VERSION "..\..\trunk\components\winTestMT\code\canApi\dbcFiles\canBus_04.dbc, created by Octave and generateRandomDbc.m on 21-Feb-2017"

NS_ :

BS_:

BU_: ECU

BO_ 577 frame_577: 2 Vector__XXX
  SG_ checksum_9_8 : 8|8@1+ (1.0,0.0) [0.0|255.0] "" ECU

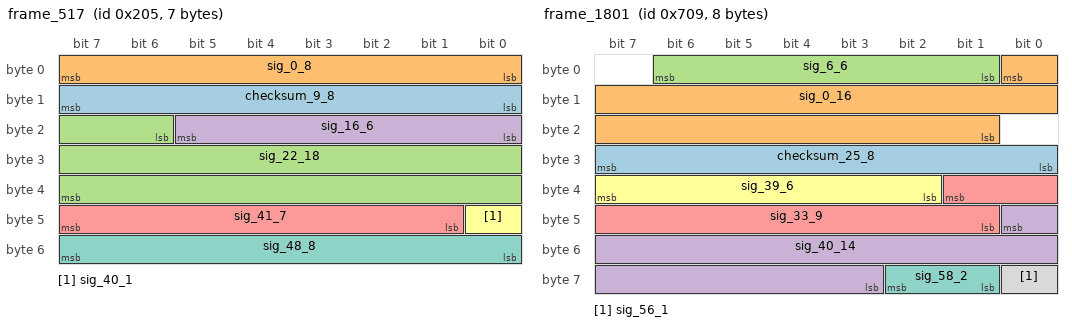
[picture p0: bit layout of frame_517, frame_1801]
BO_ 517 frame_517: 7 Vector__XXX
  SG_ checksum_9_8 : 8|8@1+ (1.0,0.0) [0.0|255.0] "" ECU
  SG_ sig_0_8 : 0|8@1- (1.0,0.0) [-128.0|126.0] "" ECU
  SG_ sig_22_18 : 22|18@1- (1.0,0.0) [-131072.0|131070.0] "" ECU
  SG_ sig_16_6 : 16|6@1- (1.0,0.0) [-32.0|30.0] "" ECU
  SG_ sig_41_7 : 41|7@1+ (0.010000000000000002,0.0) [0.0|1.2600000000000002] "V" ECU
  SG_ sig_40_1 : 40|1@1+ (1.0,0.0) [0.0|1.0] "" ECU
  SG_ sig_48_8 : 48|8@1- (0.1,0.0) [-12.8|12.600000000000001] "kWh" ECU

BO_ 1470 frame_1470: 4 Vector__XXX
  SG_ checksum_25_8 : 31|8@0+ (1.0,0.0) [0.0|255.0] "" ECU
  SG_ sig_4_12 : 4|12@0+ (1.0,0.0) [0.0|4094.0] "" ECU
  SG_ sig_5_3 : 5|3@1- (1.0,0.0) [-4.0|2.0] "" ECU
  SG_ sig_8_1 : 8|1@1+ (1.0,0.0) [0.0|1.0] "" ECU
  SG_ sig_23_6 : 23|6@0+ (1000.0,0.0) [0.0|62000.0] "kWh" ECU
  SG_ sig_16_2 : 16|2@1+ (1.0,0.0) [0.0|3.0] "" ECU

BO_ 1189 frame_1189: 8 Vector__XXX
  SG_ checksum_49_8 : 55|8@0+ (1.0,0.0) [0.0|255.0] "" ECU
  SG_ sig_29_22 : 29|22@0+ (1.0000000000000014E-12,-3.162277660168379E-6) [-3.162277660168379E-6|1.032024339831627E-6] "V" ECU
  SG_ sig_3_20 : 3|20@0- (1.0,0.0) [-524288.0|524286.0] "" ECU
  SG_ sig_7_3 : 7|3@0+ (1.0,0.0) [0.0|6.0] "" ECU
  SG_ sig_31_2 : 31|2@0+ (1.0,0.0) [0.0|3.0] "" ECU
  SG_ sig_63_8 : 63|8@0- (1.0000000000000006E-6,-3.1622776601683795E-5) [-1.5962277660168386E-4|9.437722339831629E-5] "m/s^2" ECU

BO_ 1801 frame_1801: 8 ECU
  SG_ checksum_25_8 : 31|8@0+ (1.0,0.0) [0.0|255.0] "" Vector__XXX
  SG_ sig_0_16 : 0|16@0- (1.0,0.0) [-32768.0|32766.0] "" Vector__XXX
  SG_ sig_6_6 : 6|6@0- (1.0,31.622776601683793) [-0.37722339831620744|61.622776601683796] "W" Vector__XXX
  SG_ sig_40_14 : 40|14@0+ (0.0010000000000000002,3.1622776601683795) [3.1622776601683795|19.544277660168383] "s" Vector__XXX
  SG_ sig_33_9 : 33|9@0+ (1.0000000000000007E-7,0.0) [0.0|5.100000000000004E-5] "km/h" Vector__XXX
  SG_ sig_39_6 : 39|6@0- (1.0000000000000007E-7,3.162277660168379E-6) [-3.7722339831623205E-8|6.162277660168381E-6] "kWh" Vector__XXX
  SG_ sig_58_2 : 58|2@0- (1.0,0.0) [-2.0|1.0] "" Vector__XXX
  SG_ sig_56_1 : 56|1@0+ (1.0,0.0) [0.0|1.0] "" Vector__XXX

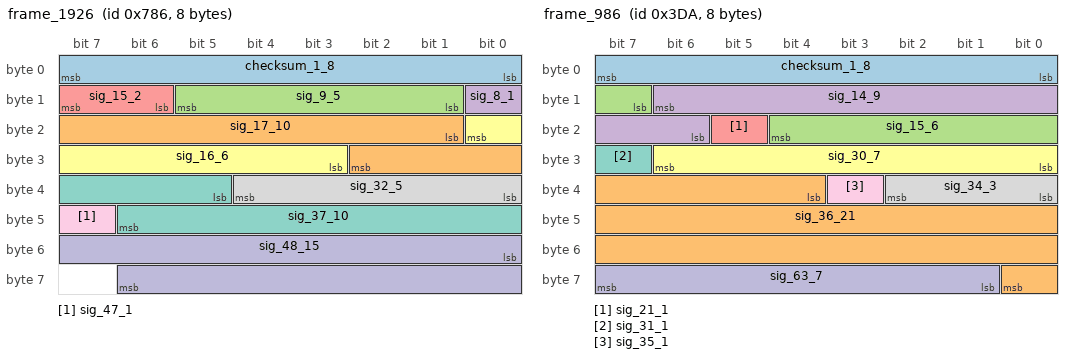
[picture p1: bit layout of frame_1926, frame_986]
BO_ 1926 frame_1926: 8 ECU
  SG_ checksum_1_8 : 7|8@0+ (1.0,0.0) [0.0|255.0] "" Vector__XXX
  SG_ sig_17_10 : 17|10@1- (1.0000000000000005E-4,0.0) [-0.05120000000000002|0.051000000000000024] "W" Vector__XXX
  SG_ sig_9_5 : 9|5@1+ (1.0,0.0) [0.0|30.0] "" Vector__XXX
  SG_ sig_8_1 : 8|1@1+ (1.0,0.0) [0.0|1.0] "" Vector__XXX
  SG_ sig_15_2 : 15|2@0- (1.0,0.0) [-2.0|1.0] "" Vector__XXX
  SG_ sig_16_6 : 16|6@0- (1.0000000000000006E-5,0.0) [-3.200000000000002E-4|3.000000000000002E-4] "m/s^2" Vector__XXX
  SG_ sig_37_10 : 37|10@1- (1.0000000000000007E-7,3.1622776601683795E-5) [-1.9577223398316243E-5|8.262277660168384E-5] "s" Vector__XXX
  SG_ sig_32_5 : 32|5@1- (1.0000000000000006E-6,0.0) [-1.600000000000001E-5|1.4000000000000008E-5] "m/s^2" Vector__XXX
  SG_ sig_47_1 : 47|1@0+ (1.0,0.0) [0.0|1.0] "" Vector__XXX
  SG_ sig_48_15 : 48|15@1- (0.0010000000000000002,31.622776601683793) [15.238776601683789|48.0047766016838] "W" Vector__XXX

BO_ 986 frame_986: 8 ECU
  SG_ checksum_1_8 : 7|8@0+ (1.0,0.0) [0.0|255.0] "" Vector__XXX
  SG_ sig_36_21 : 36|21@1- (0.010000000000000002,3162.2776601683795) [-7323.482339831622|13648.017660168382] "A" Vector__XXX
  SG_ sig_15_6 : 15|6@1- (1.0,0.0) [-32.0|30.0] "" Vector__XXX
  SG_ sig_14_9 : 14|9@0- (1.0,0.0) [-256.0|254.0] "" Vector__XXX
  SG_ sig_21_1 : 21|1@1+ (1.0,0.0) [0.0|1.0] "" Vector__XXX
  SG_ sig_30_7 : 30|7@0- (1.0000000000000006E-6,3.1622776601683795E-5) [-3.237722339831624E-5|9.362277660168383E-5] "V" Vector__XXX
  SG_ sig_31_1 : 31|1@0+ (1.0,0.0) [0.0|1.0] "" Vector__XXX
  SG_ sig_34_3 : 34|3@0- (1.0,0.0) [-4.0|2.0] "" Vector__XXX
  SG_ sig_35_1 : 35|1@0+ (1.0,0.0) [0.0|1.0] "" Vector__XXX
  SG_ sig_63_7 : 63|7@0+ (0.0010000000000000002,0.0) [0.0|0.12600000000000003] "km/h" Vector__XXX

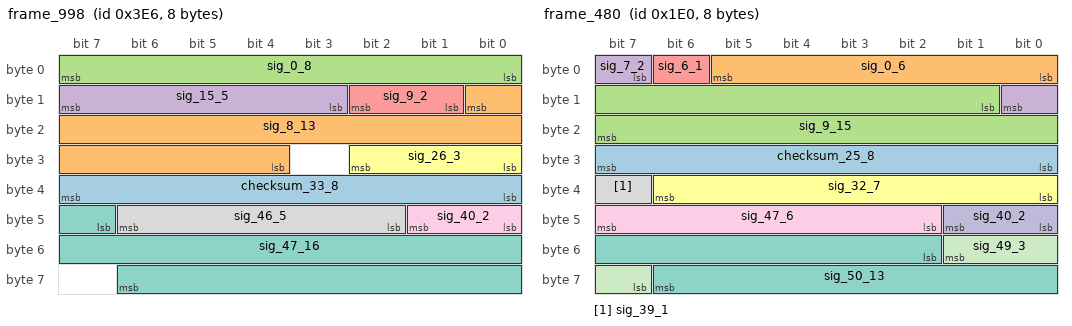
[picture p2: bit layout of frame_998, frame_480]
BO_ 998 frame_998: 8 ECU
  SG_ checksum_33_8 : 39|8@0+ (1.0,0.0) [0.0|255.0] "" Vector__XXX
  SG_ sig_8_13 : 8|13@0- (10.0,-31622.776601683792) [-72582.77660168378|9317.223398316208] "km/h" Vector__XXX
  SG_ sig_0_8 : 0|8@1+ (1.0,0.0) [0.0|254.0] "" Vector__XXX
  SG_ sig_15_5 : 15|5@0+ (1.0000000000000006E-5,3.1622776601683794E-4) [3.1622776601683794E-4|6.162277660168381E-4] "W" Vector__XXX
  SG_ sig_9_2 : 9|2@1+ (1.0,0.0) [0.0|3.0] "" Vector__XXX
  SG_ sig_26_3 : 26|3@0+ (1.0,0.0) [0.0|6.0] "" Vector__XXX
  SG_ sig_47_16 : 47|16@1- (0.010000000000000002,0.0) [-327.68000000000006|327.6600000000001] "s" Vector__XXX
  SG_ sig_46_5 : 46|5@0- (1.0000000000000005E-4,-0.0031622776601683794) [-0.0047622776601683806|-0.0017622776601683788] "m/s^2" Vector__XXX
  SG_ sig_40_2 : 40|2@1- (1.0,0.0) [-2.0|1.0] "" Vector__XXX

BO_ 480 frame_480: 8 Vector__XXX
  SG_ checksum_25_8 : 31|8@0+ (1.0,0.0) [0.0|255.0] "" ECU
  SG_ sig_0_6 : 0|6@1+ (1.0,0.0) [0.0|62.0] "" ECU
  SG_ sig_9_15 : 9|15@1+ (1.0000000000000005E-4,0.0) [0.0|3.2766000000000015] "kWh" ECU
  SG_ sig_7_2 : 7|2@1- (1.0,0.0) [-2.0|1.0] "" ECU
  SG_ sig_6_1 : 6|1@0+ (1.0,0.0) [0.0|1.0] "" ECU
  SG_ sig_32_7 : 32|7@1+ (0.1,3.1622776601683795) [3.1622776601683795|15.762277660168381] "m/s^2" ECU
  SG_ sig_50_13 : 50|13@1- (1.0,0.0) [-4096.0|4094.0] "" ECU
  SG_ sig_39_1 : 39|1@0+ (1.0,0.0) [0.0|1.0] "" ECU
  SG_ sig_47_6 : 47|6@0+ (1.0,0.0) [0.0|62.0] "km/h" ECU
  SG_ sig_40_2 : 40|2@1- (1.0,0.0) [-2.0|1.0] "" ECU
  SG_ sig_49_3 : 49|3@0- (1.0,0.0) [-4.0|2.0] "" ECU

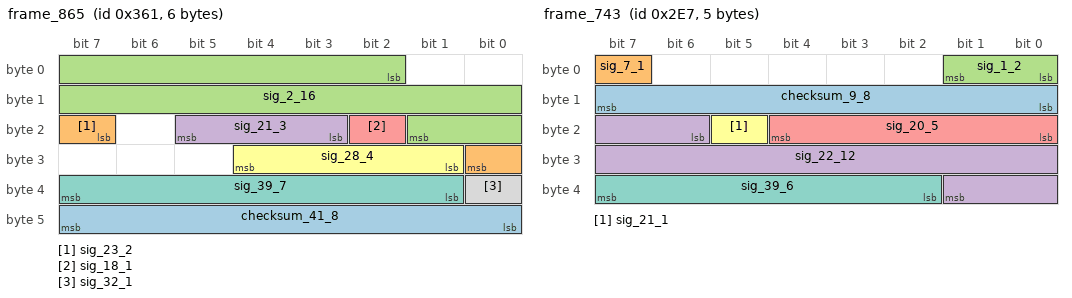
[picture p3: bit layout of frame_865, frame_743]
BO_ 865 frame_865: 6 Vector__XXX
  SG_ checksum_41_8 : 40|8@1+ (1.0,0.0) [0.0|255.0] "" ECU
  SG_ sig_23_2 : 23|2@1- (1.0,0.0) [-2.0|1.0] "" ECU
  SG_ sig_2_16 : 2|16@1- (1.0000000000000006E-6,0.03162277660168379) [-0.001145223398316228|0.06438877660168381] "km/h" ECU
  SG_ sig_21_3 : 21|3@0+ (1.0,0.0) [0.0|6.0] "" ECU
  SG_ sig_18_1 : 18|1@1+ (1.0,0.0) [0.0|1.0] "" ECU
  SG_ sig_28_4 : 28|4@0+ (1000.0,-3162.2776601683795) [-3162.2776601683795|10837.72233983162] "V" ECU
  SG_ sig_39_7 : 39|7@0+ (0.1,-3.1622776601683795) [-3.1622776601683795|9.437722339831621] "m/s^2" ECU
  SG_ sig_32_1 : 32|1@0+ (1.0,0.0) [0.0|1.0] "" ECU

BO_ 743 frame_743: 5 ECU
  SG_ checksum_9_8 : 8|8@1+ (1.0,0.0) [0.0|255.0] "" Vector__XXX
  SG_ sig_7_1 : 7|1@0+ (1.0,0.0) [0.0|1.0] "" Vector__XXX
  SG_ sig_1_2 : 1|2@0- (1.0,0.0) [-2.0|1.0] "" Vector__XXX
  SG_ sig_22_12 : 22|12@1+ (1.0,0.0) [0.0|4094.0] "" Vector__XXX
  SG_ sig_20_5 : 20|5@0+ (1.0,31.622776601683793) [31.622776601683793|61.622776601683796] "m/s^2" Vector__XXX
  SG_ sig_21_1 : 21|1@0+ (1.0,0.0) [0.0|1.0] "" Vector__XXX
  SG_ sig_39_6 : 39|6@0+ (1.0,0.0) [0.0|62.0] "" Vector__XXX

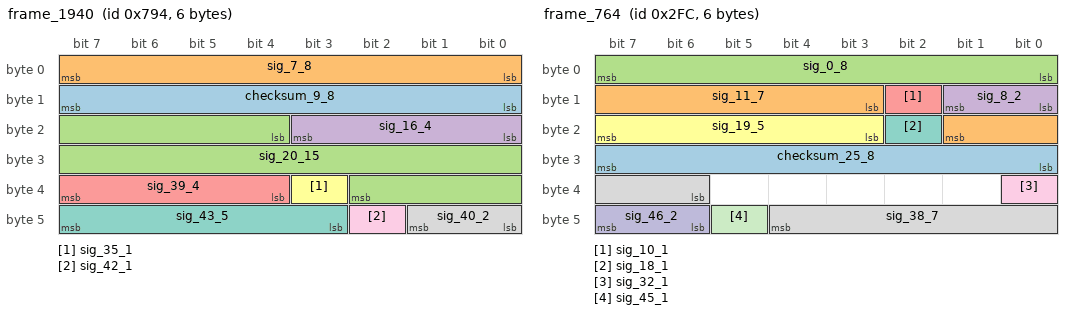
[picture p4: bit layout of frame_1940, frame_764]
BO_ 1940 frame_1940: 6 Vector__XXX
  SG_ checksum_9_8 : 8|8@1+ (1.0,0.0) [0.0|255.0] "" ECU
  SG_ sig_7_8 : 7|8@0- (100.0,3162.2776601683795) [-9637.72233983162|15762.27766016838] "km/h" ECU
  SG_ sig_20_15 : 20|15@1- (1.0000000000000006E-5,0.31622776601683794) [0.15238776601683784|0.4800477660168381] "m/s^2" ECU
  SG_ sig_16_4 : 16|4@1- (1.0000000000000006E-6,3.162277660168379E-6) [-4.8377223398316255E-6|9.162277660168383E-6] "m/s^2" ECU
  SG_ sig_39_4 : 39|4@0+ (1000.0,3162.2776601683795) [3162.2776601683795|17162.27766016838] "V" ECU
  SG_ sig_35_1 : 35|1@0+ (1.0,0.0) [0.0|1.0] "" ECU
  SG_ sig_43_5 : 43|5@1- (10.0,316.22776601683796) [156.22776601683796|456.22776601683796] "kWh" ECU
  SG_ sig_40_2 : 40|2@1+ (1.0,0.0) [0.0|3.0] "" ECU
  SG_ sig_42_1 : 42|1@0+ (1.0,0.0) [0.0|1.0] "" ECU

BO_ 764 frame_764: 6 Vector__XXX
  SG_ checksum_25_8 : 24|8@1+ (1.0,0.0) [0.0|255.0] "" ECU
  SG_ sig_11_7 : 11|7@1+ (1.0000000000000006E-5,-3.1622776601683794E-4) [-3.1622776601683794E-4|9.437722339831628E-4] "W" ECU
  SG_ sig_0_8 : 0|8@1- (1.0000000000000005E-4,-0.0031622776601683794) [-0.015962277660168386|0.009437722339831625] "kWh" ECU
  SG_ sig_8_2 : 8|2@1- (1.0,0.0) [-2.0|1.0] "" ECU
  SG_ sig_10_1 : 10|1@1+ (1.0,0.0) [0.0|1.0] "" ECU
  SG_ sig_19_5 : 19|5@1+ (1.0,0.0) [0.0|30.0] "" ECU
  SG_ sig_18_1 : 18|1@1+ (1.0,0.0) [0.0|1.0] "" ECU
  SG_ sig_38_7 : 38|7@1- (100.0,3162.2776601683795) [-3237.7223398316205|9362.27766016838] "W" ECU
  SG_ sig_32_1 : 32|1@1+ (1.0,0.0) [0.0|1.0] "" ECU
  SG_ sig_46_2 : 46|2@1- (1.0,0.0) [-2.0|1.0] "" ECU
  SG_ sig_45_1 : 45|1@1+ (1.0,0.0) [0.0|1.0] "" ECU

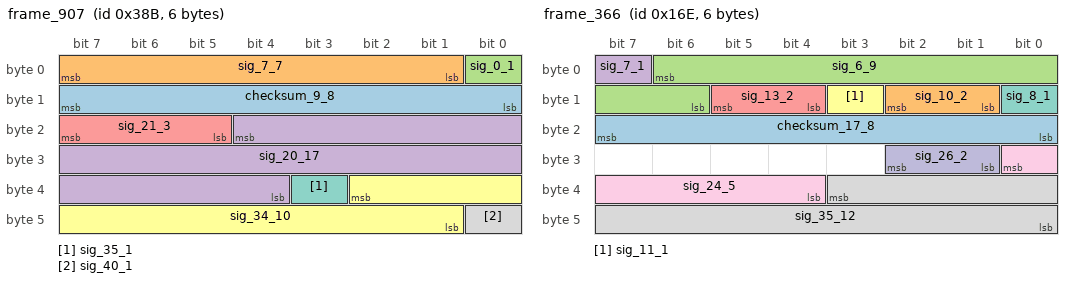
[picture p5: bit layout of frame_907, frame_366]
BO_ 907 frame_907: 6 Vector__XXX
  SG_ checksum_9_8 : 8|8@1+ (1.0,0.0) [0.0|255.0] "" ECU
  SG_ sig_7_7 : 7|7@0+ (1.0000000000000006E-6,3.1622776601683795E-5) [3.1622776601683795E-5|1.5762277660168387E-4] "km/h" ECU
  SG_ sig_0_1 : 0|1@0+ (1.0,0.0) [0.0|1.0] "" ECU
  SG_ sig_20_17 : 20|17@0- (0.1,3162.2776601683795) [-3391.322339831621|9715.67766016838] "m/s^2" ECU
  SG_ sig_21_3 : 21|3@1+ (1.0,0.0) [0.0|6.0] "" ECU
  SG_ sig_34_10 : 34|10@0- (1.0,0.0) [-512.0|510.0] "" ECU
  SG_ sig_35_1 : 35|1@1+ (1.0,0.0) [0.0|1.0] "" ECU
  SG_ sig_40_1 : 40|1@0+ (1.0,0.0) [0.0|1.0] "" ECU

BO_ 366 frame_366: 6 Vector__XXX
  SG_ checksum_17_8 : 23|8@0+ (1.0,0.0) [0.0|255.0] "" ECU
  SG_ sig_10_2 : 10|2@0- (1.0,0.0) [-2.0|1.0] "" ECU
  SG_ sig_6_9 : 6|9@0- (1.0,0.0) [-256.0|254.0] "" ECU
  SG_ sig_7_1 : 7|1@0+ (1.0,0.0) [0.0|1.0] "" ECU
  SG_ sig_13_2 : 13|2@0+ (1.0,0.0) [0.0|3.0] "" ECU
  SG_ sig_11_1 : 11|1@0+ (1.0,0.0) [0.0|1.0] "" ECU
  SG_ sig_8_1 : 8|1@0+ (1.0,0.0) [0.0|1.0] "" ECU
  SG_ sig_35_12 : 35|12@0+ (1.0000000000000005E-4,-0.31622776601683794) [-0.31622776601683794|0.09317223398316227] "V" ECU
  SG_ sig_24_5 : 24|5@0- (1.0000000000000007E-7,3.162277660168379E-6) [1.562277660168378E-6|4.56227766016838E-6] "W" ECU
  SG_ sig_26_2 : 26|2@0- (1.0,0.0) [-2.0|1.0] "" ECU

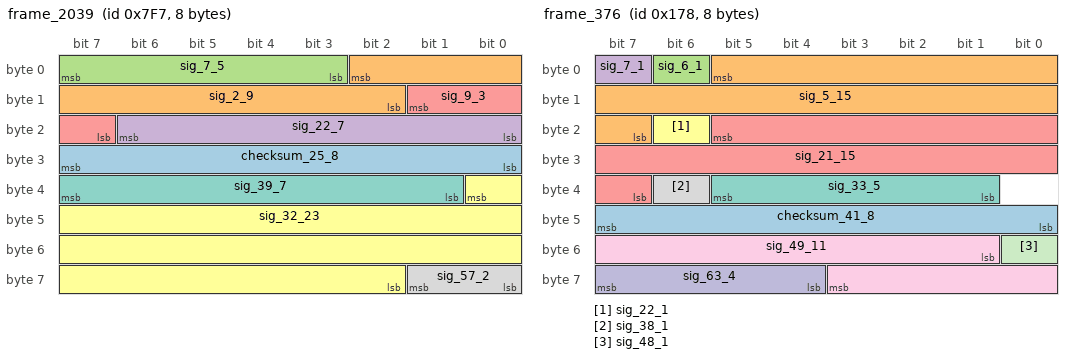
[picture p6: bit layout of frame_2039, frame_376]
BO_ 2039 frame_2039: 8 Vector__XXX
  SG_ checksum_25_8 : 24|8@1+ (1.0,0.0) [0.0|255.0] "" ECU
  SG_ sig_2_9 : 2|9@0- (1.0,0.0) [-256.0|254.0] "" ECU
  SG_ sig_7_5 : 7|5@0+ (1000.0,31622.776601683792) [31622.776601683792|61622.77660168379] "V" ECU
  SG_ sig_22_7 : 22|7@0- (0.010000000000000002,0.31622776601683794) [-0.3237722339831622|0.9362277660168381] "W" ECU
  SG_ sig_9_3 : 9|3@0+ (1.0,0.0) [0.0|6.0] "" ECU
  SG_ sig_32_23 : 32|23@0+ (0.0010000000000000002,3162.2776601683795) [3162.2776601683795|11550.883660168382] "W" ECU
  SG_ sig_39_7 : 39|7@0- (1.0,0.0) [-64.0|62.0] "" ECU
  SG_ sig_57_2 : 57|2@0+ (1.0,0.0) [0.0|3.0] "" ECU

BO_ 411 frame_411: 5 Vector__XXX
  SG_ checksum_17_8 : 16|8@1+ (1.0,0.0) [0.0|255.0] "" ECU
  SG_ sig_2_14 : 2|14@1- (10.0,31622.776601683792) [-50297.22339831621|113522.77660168378] "s" ECU
  SG_ sig_1_2 : 1|2@0+ (1.0,0.0) [0.0|3.0] "" ECU
  SG_ sig_26_10 : 26|10@1- (100.0,0.0) [-51200.0|51000.0] "kWh" ECU
  SG_ sig_38_3 : 38|3@0+ (1.0,0.0) [0.0|6.0] "" ECU
  SG_ sig_25_3 : 25|3@0- (1.0,0.0) [-4.0|2.0] "" ECU

BO_ 376 frame_376: 8 Vector__XXX
  SG_ checksum_41_8 : 40|8@1+ (1.0,0.0) [0.0|255.0] "" ECU
  SG_ sig_5_15 : 5|15@0- (1.0000000000000007E-7,-0.0031622776601683794) [-0.004800677660168381|-0.001524077660168378] "m/s^2" ECU
  SG_ sig_6_1 : 6|1@0+ (1.0,0.0) [0.0|1.0] "" ECU
  SG_ sig_7_1 : 7|1@0+ (1.0,0.0) [0.0|1.0] "" ECU
  SG_ sig_21_15 : 21|15@0+ (1.0000000000000008E-8,0.0) [0.0|3.276600000000003E-4] "km/h" ECU
  SG_ sig_22_1 : 22|1@0+ (1.0,0.0) [0.0|1.0] "" ECU
  SG_ sig_33_5 : 33|5@1+ (0.0010000000000000002,-0.03162277660168379) [-0.03162277660168379|-0.0016227766016837855] "s" ECU
  SG_ sig_38_1 : 38|1@0+ (1.0,0.0) [0.0|1.0] "" ECU
  SG_ sig_49_11 : 49|11@1- (10.0,3162.2776601683795) [-7077.72233983162|13382.27766016838] "s" ECU
  SG_ sig_63_4 : 63|4@0- (0.010000000000000002,-0.03162277660168379) [-0.1116227766016838|0.02837722339831622] "km/h" ECU
  SG_ sig_48_1 : 48|1@0+ (1.0,0.0) [0.0|1.0] "" ECU

BO_ 655 frame_655: 5 ECU
  SG_ checksum_25_8 : 31|8@0+ (1.0,0.0) [0.0|255.0] "" Vector__XXX
  SG_ sig_6_10 : 6|10@0- (1.0,0.0) [-512.0|510.0] "" Vector__XXX
  SG_ sig_7_1 : 7|1@0+ (1.0,0.0) [0.0|1.0] "" Vector__XXX
  SG_ sig_11_12 : 11|12@0+ (1.0,0.0) [0.0|4094.0] "" Vector__XXX
  SG_ sig_12_1 : 12|1@0+ (1.0,0.0) [0.0|1.0] "" Vector__XXX
  SG_ sig_39_8 : 39|8@0- (1.0000000000000007E-7,-3.162277660168379E-6) [-1.596227766016839E-5|9.43772233983163E-6] "m/s^2" Vector__XXX

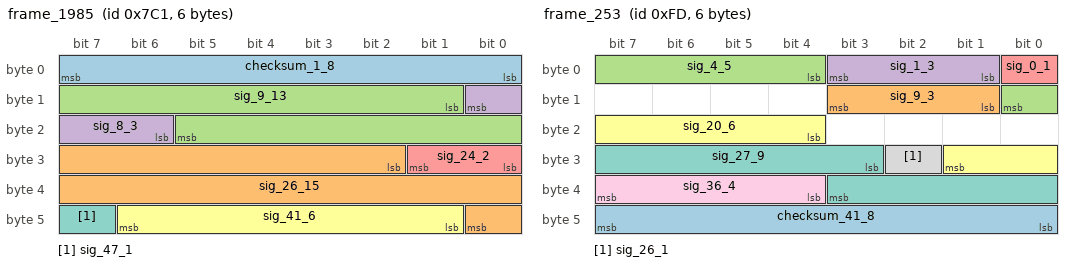
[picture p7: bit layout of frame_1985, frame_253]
BO_ 1985 frame_1985: 6 Vector__XXX
  SG_ checksum_1_8 : 7|8@0+ (1.0,0.0) [0.0|255.0] "" ECU
  SG_ sig_26_15 : 26|15@1- (1.0000000000000011E-10,-3.162277660168379E-6) [-4.800677660168381E-6|-1.5240776601683775E-6] "W" ECU
  SG_ sig_9_13 : 9|13@1- (1.0,0.0) [-4096.0|4094.0] "" ECU
  SG_ sig_8_3 : 8|3@0- (1.0,0.0) [-4.0|2.0] "" ECU
  SG_ sig_24_2 : 24|2@1+ (1.0,0.0) [0.0|3.0] "" ECU
  SG_ sig_41_6 : 41|6@1- (1.0,0.0) [-32.0|30.0] "" ECU
  SG_ sig_47_1 : 47|1@0+ (1.0,0.0) [0.0|1.0] "" ECU

BO_ 1572 frame_1572: 2 Vector__XXX
  SG_ checksum_1_8 : 7|8@0+ (1.0,0.0) [0.0|255.0] "" ECU
  SG_ sig_8_1 : 8|1@1+ (1.0,0.0) [0.0|1.0] "" ECU

BO_ 253 frame_253: 6 Vector__XXX
  SG_ checksum_41_8 : 40|8@1+ (1.0,0.0) [0.0|255.0] "" ECU
  SG_ sig_9_3 : 9|3@1- (1.0,0.0) [-4.0|2.0] "" ECU
  SG_ sig_4_5 : 4|5@1- (1.0000000000000006E-5,3.1622776601683794E-4) [1.5622776601683785E-4|4.5622776601683804E-4] "A" ECU
  SG_ sig_1_3 : 1|3@1- (1.0,0.0) [-4.0|2.0] "" ECU
  SG_ sig_0_1 : 0|1@1+ (1.0,0.0) [0.0|1.0] "" ECU
  SG_ sig_20_6 : 20|6@1- (0.1,0.0) [-3.2|3.0] "km/h" ECU
  SG_ sig_27_9 : 27|9@1+ (1.0,0.0) [0.0|510.0] "" ECU
  SG_ sig_26_1 : 26|1@1+ (1.0,0.0) [0.0|1.0] "" ECU
  SG_ sig_36_4 : 36|4@1- (1.0,0.0) [-8.0|6.0] "" ECU

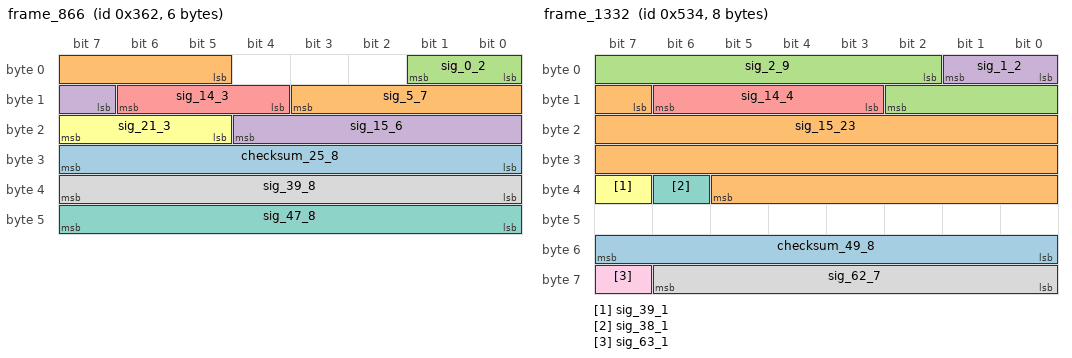
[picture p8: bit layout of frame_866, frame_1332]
BO_ 866 frame_866: 6 Vector__XXX
  SG_ checksum_25_8 : 24|8@1+ (1.0,0.0) [0.0|255.0] "" ECU
  SG_ sig_5_7 : 5|7@1- (1.0,0.0) [-64.0|62.0] "" ECU
  SG_ sig_0_2 : 0|2@1- (1.0,0.0) [-2.0|1.0] "" ECU
  SG_ sig_15_6 : 15|6@1+ (1000.0,-31622.776601683792) [-31622.776601683792|30377.223398316208] "V" ECU
  SG_ sig_14_3 : 14|3@0- (1.0,0.0) [-4.0|2.0] "" ECU
  SG_ sig_21_3 : 21|3@1+ (1.0,0.0) [0.0|6.0] "" ECU
  SG_ sig_47_8 : 47|8@0+ (1.0,0.0) [0.0|254.0] "" ECU
  SG_ sig_39_8 : 39|8@0+ (1.0,0.0) [0.0|254.0] "" ECU

BO_ 1332 frame_1332: 8 ECU
  SG_ checksum_49_8 : 55|8@0+ (1.0,0.0) [0.0|255.0] "" Vector__XXX
  SG_ sig_15_23 : 15|23@1- (1.000000000000001E-11,0.0) [-4.1943040000000045E-5|4.1943020000000043E-5] "W" Vector__XXX
  SG_ sig_2_9 : 2|9@1- (1.0,0.0) [-256.0|254.0] "" Vector__XXX
  SG_ sig_1_2 : 1|2@0- (1.0,0.0) [-2.0|1.0] "" Vector__XXX
  SG_ sig_14_4 : 14|4@0- (1.0,0.0) [-8.0|6.0] "" Vector__XXX
  SG_ sig_39_1 : 39|1@1+ (1.0,0.0) [0.0|1.0] "" Vector__XXX
  SG_ sig_38_1 : 38|1@0+ (1.0,0.0) [0.0|1.0] "" Vector__XXX
  SG_ sig_62_7 : 62|7@0- (1.0000000000000006E-5,0.0) [-6.400000000000004E-4|6.200000000000003E-4] "km/h" Vector__XXX
  SG_ sig_63_1 : 63|1@1+ (1.0,0.0) [0.0|1.0] "" Vector__XXX

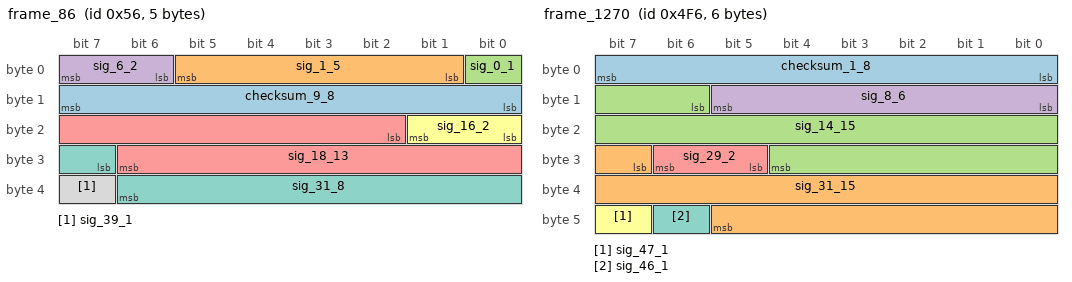
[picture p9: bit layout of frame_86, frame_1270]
BO_ 86 frame_86: 5 ECU
  SG_ checksum_9_8 : 8|8@1+ (1.0,0.0) [0.0|255.0] "" Vector__XXX
  SG_ sig_1_5 : 1|5@1- (100.0,3162.2776601683795) [1562.2776601683795|4562.27766016838] "km/h" Vector__XXX
  SG_ sig_0_1 : 0|1@1+ (1.0,0.0) [0.0|1.0] "" Vector__XXX
  SG_ sig_6_2 : 6|2@1- (1.0,0.0) [-2.0|1.0] "" Vector__XXX
  SG_ sig_18_13 : 18|13@1+ (1.0,0.0) [0.0|8190.0] "" Vector__XXX
  SG_ sig_16_2 : 16|2@1+ (1.0,0.0) [0.0|3.0] "" Vector__XXX
  SG_ sig_31_8 : 31|8@1+ (1.0,0.0) [0.0|254.0] "" Vector__XXX
  SG_ sig_39_1 : 39|1@1+ (1.0,0.0) [0.0|1.0] "" Vector__XXX

BO_ 1270 frame_1270: 6 Vector__XXX
  SG_ checksum_1_8 : 7|8@0+ (1.0,0.0) [0.0|255.0] "" ECU
  SG_ sig_31_15 : 31|15@1- (1.0,0.0) [-16384.0|16382.0] "" ECU
  SG_ sig_14_15 : 14|15@1+ (0.010000000000000002,0.0) [0.0|327.6600000000001] "W" ECU
  SG_ sig_8_6 : 8|6@1+ (1000.0,-31622.776601683792) [-31622.776601683792|30377.223398316208] "W" ECU
  SG_ sig_29_2 : 29|2@1- (1.0,0.0) [-2.0|1.0] "" ECU
  SG_ sig_47_1 : 47|1@0+ (1.0,0.0) [0.0|1.0] "" ECU
  SG_ sig_46_1 : 46|1@0+ (1.0,0.0) [0.0|1.0] "" ECU

BO_ 1002 frame_1002: 6 ECU
  SG_ checksum_1_8 : 0|8@1+ (1.0,0.0) [0.0|255.0] "" Vector__XXX
  SG_ sig_32_9 : 32|9@0+ (1.0,0.0) [0.0|510.0] "" Vector__XXX
  SG_ sig_14_18 : 14|18@0- (1.0,0.0) [-131072.0|131070.0] "" Vector__XXX
  SG_ sig_25_3 : 25|3@1+ (1.0,0.0) [0.0|6.0] "" Vector__XXX
  SG_ sig_24_7 : 24|7@0+ (1.0000000000000005E-4,-0.0031622776601683794) [-0.0031622776601683794|0.009437722339831625] "s" Vector__XXX
  SG_ sig_33_1 : 33|1@1+ (1.0,0.0) [0.0|1.0] "" Vector__XXX

BO_ 1957 frame_1957: 6 ECU
  SG_ checksum_41_8 : 47|8@0+ (1.0,0.0) [0.0|255.0] "" Vector__XXX
  SG_ sig_30_15 : 30|15@0+ (0.0010000000000000002,0.0) [0.0|32.766000000000005] "W" Vector__XXX
  SG_ sig_4_17 : 4|17@0- (1.0000000000000006E-5,0.31622776601683794) [-0.33913223398316245|0.9715677660168383] "s" Vector__XXX
  SG_ sig_7_3 : 7|3@0+ (1.0,0.0) [0.0|6.0] "" Vector__XXX
  SG_ sig_19_5 : 19|5@0+ (1.0,0.0) [0.0|30.0] "" Vector__XXX

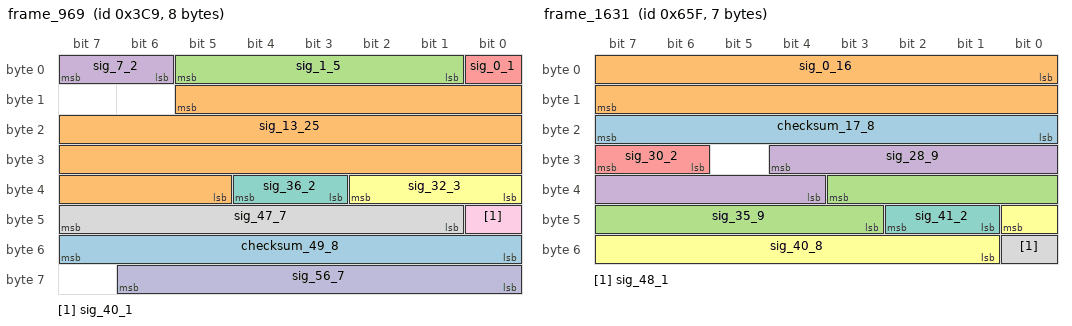
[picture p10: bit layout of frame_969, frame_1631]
BO_ 969 frame_969: 8 ECU
  SG_ checksum_49_8 : 55|8@0+ (1.0,0.0) [0.0|255.0] "" Vector__XXX
  SG_ sig_13_25 : 13|25@0+ (1.000000000000001E-11,-3.1622776601683794E-4) [-3.1622776601683794E-4|1.9316533983162445E-5] "m/s^2" Vector__XXX
  SG_ sig_1_5 : 1|5@1- (1.0,0.0) [-16.0|14.0] "" Vector__XXX
  SG_ sig_7_2 : 7|2@0+ (1.0,0.0) [0.0|3.0] "" Vector__XXX
  SG_ sig_0_1 : 0|1@1+ (1.0,0.0) [0.0|1.0] "" Vector__XXX
  SG_ sig_32_3 : 32|3@1+ (1.0,0.0) [0.0|6.0] "" Vector__XXX
  SG_ sig_36_2 : 36|2@0- (1.0,0.0) [-2.0|1.0] "" Vector__XXX
  SG_ sig_47_7 : 47|7@0+ (1.0,0.0) [0.0|126.0] "" Vector__XXX
  SG_ sig_40_1 : 40|1@1+ (1.0,0.0) [0.0|1.0] "" Vector__XXX
  SG_ sig_56_7 : 56|7@1- (100.0,0.0) [-6400.0|6200.0] "km/h" Vector__XXX

BO_ 1631 frame_1631: 7 Vector__XXX
  SG_ checksum_17_8 : 16|8@1+ (1.0,0.0) [0.0|255.0] "" ECU
  SG_ sig_0_16 : 0|16@1- (0.010000000000000002,316.22776601683796) [-11.452233983162103|643.887766016838] "A" ECU
  SG_ sig_35_9 : 35|9@0+ (1.0,0.0) [0.0|510.0] "" ECU
  SG_ sig_28_9 : 28|9@0+ (100.0,31622.776601683792) [31622.776601683792|82622.77660168378] "V" ECU
  SG_ sig_30_2 : 30|2@1+ (1.0,0.0) [0.0|3.0] "" ECU
  SG_ sig_40_8 : 40|8@0+ (1000.0,0.0) [0.0|254000.0] "V" ECU
  SG_ sig_41_2 : 41|2@1+ (1.0,0.0) [0.0|3.0] "" ECU
  SG_ sig_48_1 : 48|1@1+ (1.0,0.0) [0.0|1.0] "" ECU

BO_ 823 frame_823: 7 Vector__XXX
  SG_ checksum_41_8 : 47|8@0+ (1.0,0.0) [0.0|255.0] "" ECU
  SG_ sig_11_10 : 11|10@0+ (1.0000000000000006E-5,0.0) [0.0|0.010220000000000007] "V" ECU
  SG_ sig_0_8 : 0|8@1- (1000.0,0.0) [-128000.0|126000.0] "V" ECU
  SG_ sig_14_3 : 14|3@0- (1.0,0.0) [-4.0|2.0] "" ECU
  SG_ sig_15_1 : 15|1@0+ (1.0,0.0) [0.0|1.0] "" ECU
  SG_ sig_17_18 : 17|18@0- (1.0000000000000011E-10,3.162277660168379E-6) [-9.944922339831635E-6|1.6269277660168393E-5] "W" ECU
  SG_ sig_48_8 : 48|8@1- (1.0000000000000005E-4,-0.0031622776601683794) [-0.015962277660168386|0.009437722339831625] "V" ECU

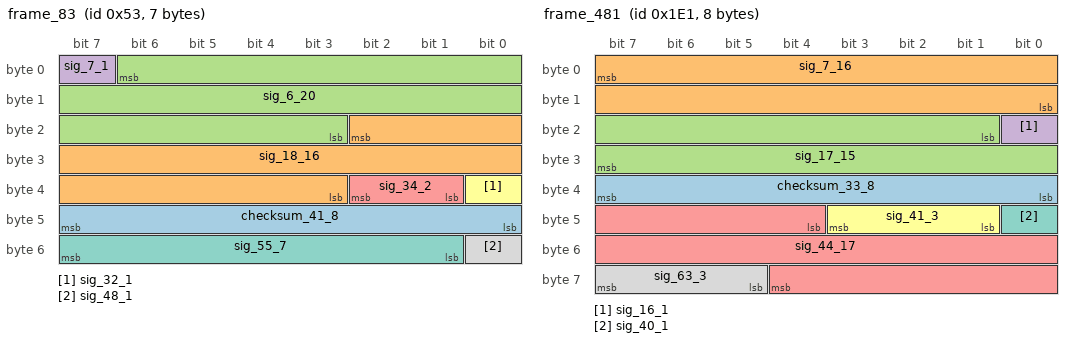
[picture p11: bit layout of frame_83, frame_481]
BO_ 83 frame_83: 7 Vector__XXX
  SG_ checksum_41_8 : 47|8@0+ (1.0,0.0) [0.0|255.0] "" ECU
  SG_ sig_18_16 : 18|16@0- (1.0,0.0) [-32768.0|32766.0] "" ECU
  SG_ sig_6_20 : 6|20@0- (1.0,0.0) [-524288.0|524286.0] "" ECU
  SG_ sig_7_1 : 7|1@0+ (1.0,0.0) [0.0|1.0] "" ECU
  SG_ sig_34_2 : 34|2@0+ (1.0,0.0) [0.0|3.0] "" ECU
  SG_ sig_32_1 : 32|1@0+ (1.0,0.0) [0.0|1.0] "" ECU
  SG_ sig_55_7 : 55|7@0- (1.0,0.0) [-64.0|62.0] "" ECU
  SG_ sig_48_1 : 48|1@0+ (1.0,0.0) [0.0|1.0] "" ECU

BO_ 481 frame_481: 8 Vector__XXX
  SG_ checksum_33_8 : 32|8@1+ (1.0,0.0) [0.0|255.0] "" ECU
  SG_ sig_7_16 : 7|16@0+ (1.0000000000000005E-4,0.0) [0.0|6.553400000000003] "s" ECU
  SG_ sig_17_15 : 17|15@1- (1.0000000000000006E-5,0.31622776601683794) [0.15238776601683784|0.4800477660168381] "W" ECU
  SG_ sig_16_1 : 16|1@0+ (1.0,0.0) [0.0|1.0] "" ECU
  SG_ sig_44_17 : 44|17@1+ (1.0000000000000008E-8,3.1622776601683794E-4) [3.1622776601683794E-4|0.001626927766016839] "s" ECU
  SG_ sig_41_3 : 41|3@1+ (1.0,0.0) [0.0|6.0] "" ECU
  SG_ sig_40_1 : 40|1@1+ (1.0,0.0) [0.0|1.0] "" ECU
  SG_ sig_63_3 : 63|3@0+ (1.0,0.0) [0.0|6.0] "" ECU

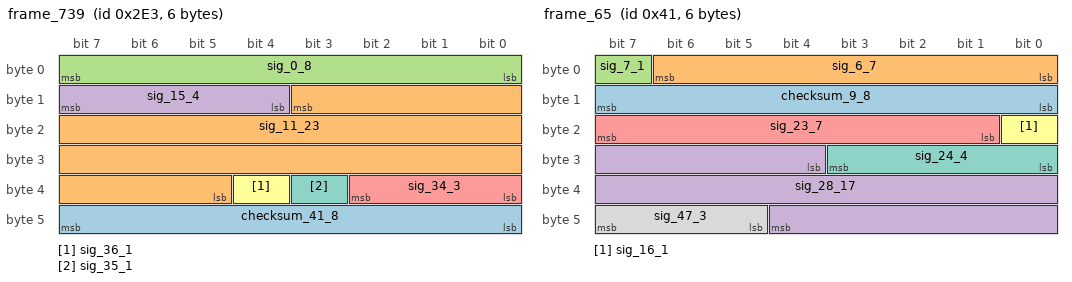
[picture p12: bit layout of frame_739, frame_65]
BO_ 739 frame_739: 6 ECU
  SG_ checksum_41_8 : 40|8@1+ (1.0,0.0) [0.0|255.0] "" Vector__XXX
  SG_ sig_11_23 : 11|23@0+ (1.0000000000000007E-7,0.0) [0.0|0.8388606000000006] "A" Vector__XXX
  SG_ sig_0_8 : 0|8@1- (1.0,0.0) [-128.0|126.0] "" Vector__XXX
  SG_ sig_15_4 : 15|4@0- (10.0,31.622776601683793) [-48.377223398316204|91.6227766016838] "kWh" Vector__XXX
  SG_ sig_34_3 : 34|3@0+ (1.0,0.0) [0.0|6.0] "" Vector__XXX
  SG_ sig_36_1 : 36|1@1+ (1.0,0.0) [0.0|1.0] "" Vector__XXX
  SG_ sig_35_1 : 35|1@1+ (1.0,0.0) [0.0|1.0] "" Vector__XXX

BO_ 65 frame_65: 6 Vector__XXX
  SG_ checksum_9_8 : 8|8@1+ (1.0,0.0) [0.0|255.0] "" ECU
  SG_ sig_6_7 : 6|7@0+ (1.0000000000000006E-6,0.0) [0.0|1.2600000000000008E-4] "s" ECU
  SG_ sig_7_1 : 7|1@1+ (1.0,0.0) [0.0|1.0] "" ECU
  SG_ sig_28_17 : 28|17@1+ (1.0,0.0) [0.0|131070.0] "" ECU
  SG_ sig_23_7 : 23|7@0- (1.0000000000000005E-4,-0.0031622776601683794) [-0.009562277660168383|0.003037722339831623] "W" ECU
  SG_ sig_16_1 : 16|1@1+ (1.0,0.0) [0.0|1.0] "" ECU
  SG_ sig_24_4 : 24|4@1+ (0.0010000000000000002,0.0031622776601683794) [0.0031622776601683794|0.017162277660168382] "A" ECU
  SG_ sig_47_3 : 47|3@0- (1.0,0.0) [-4.0|2.0] "" ECU

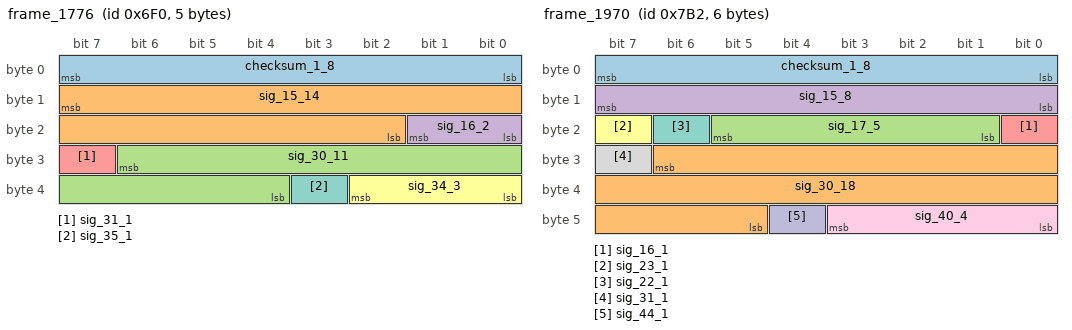
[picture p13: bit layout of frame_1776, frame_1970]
BO_ 1776 frame_1776: 5 Vector__XXX
  SG_ checksum_1_8 : 0|8@1+ (1.0,0.0) [0.0|255.0] "" ECU
  SG_ sig_15_14 : 15|14@0+ (1.0,0.0) [0.0|16382.0] "" ECU
  SG_ sig_30_11 : 30|11@0+ (1.0,0.0) [0.0|2046.0] "" ECU
  SG_ sig_16_2 : 16|2@1+ (1.0,0.0) [0.0|3.0] "" ECU
  SG_ sig_31_1 : 31|1@0+ (1.0,0.0) [0.0|1.0] "" ECU
  SG_ sig_34_3 : 34|3@0+ (1.0,0.0) [0.0|6.0] "" ECU
  SG_ sig_35_1 : 35|1@0+ (1.0,0.0) [0.0|1.0] "" ECU

BO_ 11 frame_11: 5 Vector__XXX
  SG_ checksum_17_8 : 16|8@1+ (1.0,0.0) [0.0|255.0] "" ECU
  SG_ sig_8_8 : 8|8@1- (1.0,0.0) [-128.0|126.0] "" ECU
  SG_ sig_7_8 : 7|8@0- (1.0000000000000007E-7,3.162277660168379E-6) [-9.63772233983163E-6|1.576227766016839E-5] "A" ECU
  SG_ sig_24_9 : 24|9@1+ (1.0,0.0) [0.0|510.0] "" ECU
  SG_ sig_33_5 : 33|5@1+ (1000.0,0.0) [0.0|30000.0] "m/s^2" ECU
  SG_ sig_39_2 : 39|2@0- (1.0,0.0) [-2.0|1.0] "" ECU

BO_ 484 frame_484: 3 ECU
  SG_ checksum_17_8 : 23|8@0+ (1.0,0.0) [0.0|255.0] "" Vector__XXX
  SG_ sig_0_6 : 0|6@0+ (1.0,31.622776601683793) [31.622776601683793|93.6227766016838] "A" Vector__XXX
  SG_ sig_7_3 : 7|3@0- (1.0,0.0) [-4.0|2.0] "" Vector__XXX
  SG_ sig_4_4 : 4|4@0- (10000.0,0.0) [-80000.0|60000.0] "s" Vector__XXX
  SG_ sig_10_3 : 10|3@0- (1.0,0.0) [-4.0|2.0] "" Vector__XXX

BO_ 1970 frame_1970: 6 ECU
  SG_ checksum_1_8 : 7|8@0+ (1.0,0.0) [0.0|255.0] "" Vector__XXX
  SG_ sig_30_18 : 30|18@0- (1.0000000000000007E-7,0.0031622776601683794) [-0.00994492233983163|0.016269277660168387] "km/h" Vector__XXX
  SG_ sig_17_5 : 17|5@1- (0.1,-3.1622776601683795) [-4.76227766016838|-1.7622776601683794] "km/h" Vector__XXX
  SG_ sig_15_8 : 15|8@0- (0.010000000000000002,0.31622776601683794) [-0.9637722339831623|1.5762277660168382] "V" Vector__XXX
  SG_ sig_16_1 : 16|1@1+ (1.0,0.0) [0.0|1.0] "" Vector__XXX
  SG_ sig_23_1 : 23|1@1+ (1.0,0.0) [0.0|1.0] "" Vector__XXX
  SG_ sig_22_1 : 22|1@0+ (1.0,0.0) [0.0|1.0] "" Vector__XXX
  SG_ sig_31_1 : 31|1@1+ (1.0,0.0) [0.0|1.0] "" Vector__XXX
  SG_ sig_40_4 : 40|4@1- (0.010000000000000002,0.0) [-0.08000000000000002|0.06000000000000001] "s" Vector__XXX
  SG_ sig_44_1 : 44|1@0+ (1.0,0.0) [0.0|1.0] "" Vector__XXX

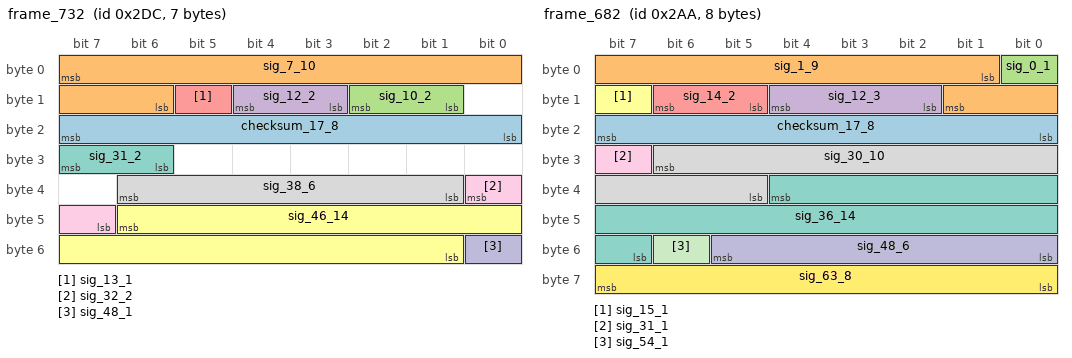
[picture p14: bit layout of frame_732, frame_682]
BO_ 732 frame_732: 7 Vector__XXX
  SG_ checksum_17_8 : 23|8@0+ (1.0,0.0) [0.0|255.0] "" ECU
  SG_ sig_7_10 : 7|10@0+ (1.0000000000000008E-8,0.0) [0.0|1.0220000000000009E-5] "A" ECU
  SG_ sig_10_2 : 10|2@0- (1.0,0.0) [-2.0|1.0] "" ECU
  SG_ sig_12_2 : 12|2@0+ (1.0,0.0) [0.0|3.0] "" ECU
  SG_ sig_13_1 : 13|1@0+ (1.0,0.0) [0.0|1.0] "" ECU
  SG_ sig_46_14 : 46|14@0- (1.0000000000000007E-7,0.0) [-8.192000000000006E-4|8.190000000000006E-4] "V" ECU
  SG_ sig_31_2 : 31|2@0+ (1.0,0.0) [0.0|3.0] "" ECU
  SG_ sig_38_6 : 38|6@0- (1.0,0.0) [-32.0|30.0] "" ECU
  SG_ sig_32_2 : 32|2@0- (1.0,0.0) [-2.0|1.0] "" ECU
  SG_ sig_48_1 : 48|1@0+ (1.0,0.0) [0.0|1.0] "" ECU

BO_ 682 frame_682: 8 Vector__XXX
  SG_ checksum_17_8 : 23|8@0+ (1.0,0.0) [0.0|255.0] "" ECU
  SG_ sig_1_9 : 1|9@1+ (1.0,0.0) [0.0|510.0] "" ECU
  SG_ sig_0_1 : 0|1@1+ (1.0,0.0) [0.0|1.0] "" ECU
  SG_ sig_12_3 : 12|3@0- (1.0,0.0) [-4.0|2.0] "" ECU
  SG_ sig_14_2 : 14|2@0- (1.0,0.0) [-2.0|1.0] "" ECU
  SG_ sig_15_1 : 15|1@0+ (1.0,0.0) [0.0|1.0] "" ECU
  SG_ sig_36_14 : 36|14@0+ (1.0,0.0) [0.0|16382.0] "" ECU
  SG_ sig_30_10 : 30|10@0- (100.0,31622.776601683792) [-19577.223398316208|82622.77660168378] "s" ECU
  SG_ sig_31_1 : 31|1@1+ (1.0,0.0) [0.0|1.0] "" ECU
  SG_ sig_48_6 : 48|6@1+ (1.0,31.622776601683793) [31.622776601683793|93.6227766016838] "W" ECU
  SG_ sig_54_1 : 54|1@1+ (1.0,0.0) [0.0|1.0] "" ECU
  SG_ sig_63_8 : 63|8@0- (0.0010000000000000002,0.0) [-0.12800000000000003|0.12600000000000003] "W" ECU

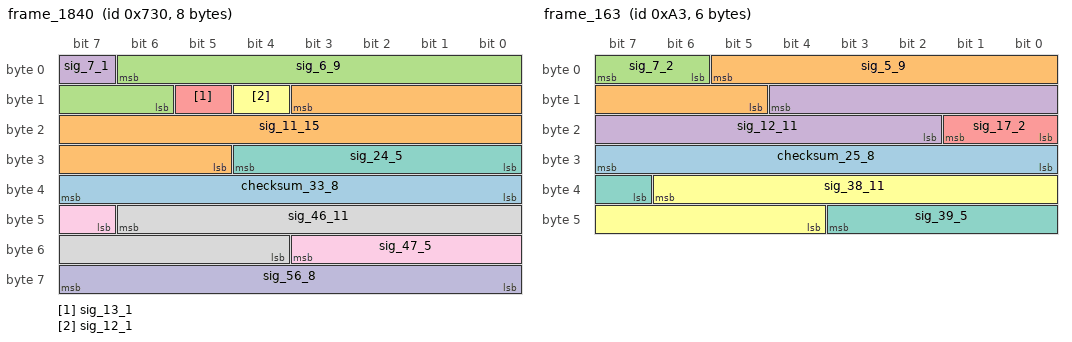
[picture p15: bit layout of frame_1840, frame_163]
BO_ 1840 frame_1840: 8 Vector__XXX
  SG_ checksum_33_8 : 39|8@0+ (1.0,0.0) [0.0|255.0] "" ECU
  SG_ sig_11_15 : 11|15@0+ (1.0000000000000005E-4,3.1622776601683795) [3.1622776601683795|6.438877660168381] "m/s^2" ECU
  SG_ sig_6_9 : 6|9@0+ (1.0000000000000005E-4,-0.03162277660168379) [-0.03162277660168379|0.019377223398316233] "A" ECU
  SG_ sig_7_1 : 7|1@0+ (1.0,0.0) [0.0|1.0] "" ECU
  SG_ sig_13_1 : 13|1@1+ (1.0,0.0) [0.0|1.0] "" ECU
  SG_ sig_12_1 : 12|1@1+ (1.0,0.0) [0.0|1.0] "" ECU
  SG_ sig_24_5 : 24|5@1- (1.0000000000000006E-5,3.1622776601683794E-4) [1.5622776601683785E-4|4.5622776601683804E-4] "W" ECU
  SG_ sig_46_11 : 46|11@0- (0.010000000000000002,0.0) [-10.240000000000002|10.220000000000002] "s" ECU
  SG_ sig_47_5 : 47|5@1- (1.0000000000000006E-5,3.1622776601683794E-4) [1.5622776601683785E-4|4.5622776601683804E-4] "kWh" ECU
  SG_ sig_56_8 : 56|8@1- (100.0,0.0) [-12800.0|12600.0] "km/h" ECU

BO_ 2036 frame_2036: 7 Vector__XXX
  SG_ checksum_17_8 : 16|8@1+ (1.0,0.0) [0.0|255.0] "" ECU
  SG_ sig_5_11 : 5|11@1- (1.0,0.0) [-1024.0|1022.0] "" ECU
  SG_ sig_42_11 : 42|11@1+ (100.0,31622.776601683792) [31622.776601683792|236222.77660168378] "kWh" ECU
  SG_ sig_24_14 : 24|14@1+ (1.0,0.0) [0.0|16382.0] "" ECU
  SG_ sig_55_3 : 55|3@0- (1.0,0.0) [-4.0|2.0] "" ECU

BO_ 163 frame_163: 6 ECU
  SG_ checksum_25_8 : 24|8@1+ (1.0,0.0) [0.0|255.0] "" Vector__XXX
  SG_ sig_5_9 : 5|9@0+ (0.0010000000000000002,0.0) [0.0|0.5100000000000001] "V" Vector__XXX
  SG_ sig_7_2 : 7|2@0- (1.0,0.0) [-2.0|1.0] "" Vector__XXX
  SG_ sig_12_11 : 12|11@0- (1.0,0.0) [-1024.0|1022.0] "" Vector__XXX
  SG_ sig_17_2 : 17|2@0+ (1.0,0.0) [0.0|3.0] "" Vector__XXX
  SG_ sig_38_11 : 38|11@0- (1.0000000000000007E-7,-3.1622776601683795E-5) [-1.3402277660168387E-4|7.057722339831628E-5] "W" Vector__XXX
  SG_ sig_39_5 : 39|5@1+ (0.010000000000000002,0.0) [0.0|0.30000000000000004] "A" Vector__XXX

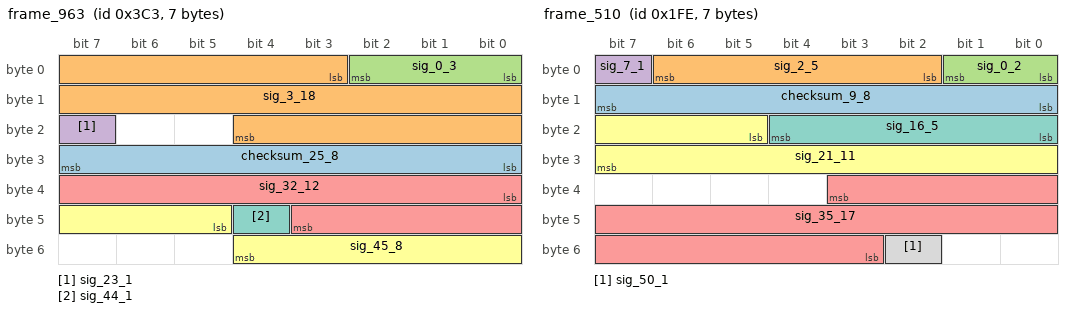
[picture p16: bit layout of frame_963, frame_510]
BO_ 963 frame_963: 7 Vector__XXX
  SG_ checksum_25_8 : 24|8@1+ (1.0,0.0) [0.0|255.0] "" ECU
  SG_ sig_3_18 : 3|18@1+ (1.0000000000000007E-7,-0.0031622776601683794) [-0.0031622776601683794|0.02305192233983164] "m/s^2" ECU
  SG_ sig_0_3 : 0|3@1+ (1.0,0.0) [0.0|6.0] "" ECU
  SG_ sig_23_1 : 23|1@1+ (1.0,0.0) [0.0|1.0] "" ECU
  SG_ sig_32_12 : 32|12@1- (1.0000000000000006E-5,0.0) [-0.020480000000000012|0.020460000000000013] "V" ECU
  SG_ sig_45_8 : 45|8@1+ (1.0000000000000007E-7,-3.162277660168379E-6) [-3.162277660168379E-6|2.2237722339831637E-5] "km/h" ECU
  SG_ sig_44_1 : 44|1@1+ (1.0,0.0) [0.0|1.0] "" ECU

BO_ 510 frame_510: 7 Vector__XXX
  SG_ checksum_9_8 : 15|8@0+ (1.0,0.0) [0.0|255.0] "" ECU
  SG_ sig_2_5 : 2|5@1- (0.1,-3.1622776601683795) [-4.76227766016838|-1.7622776601683794] "A" ECU
  SG_ sig_0_2 : 0|2@1+ (1.0,0.0) [0.0|3.0] "" ECU
  SG_ sig_7_1 : 7|1@1+ (1.0,0.0) [0.0|1.0] "" ECU
  SG_ sig_35_17 : 35|17@0+ (0.1,3162.2776601683795) [3162.2776601683795|16269.27766016838] "V" ECU
  SG_ sig_21_11 : 21|11@1- (1.0000000000000008E-8,3.162277660168379E-6) [-7.0777223398316295E-6|1.3382277660168388E-5] "kWh" ECU
  SG_ sig_16_5 : 16|5@1+ (0.010000000000000002,0.31622776601683794) [0.31622776601683794|0.616227766016838] "V" ECU
  SG_ sig_50_1 : 50|1@1+ (1.0,0.0) [0.0|1.0] "" ECU

BO_ 948 frame_948: 8 ECU
  SG_ checksum_1_8 : 0|8@1+ (1.0,0.0) [0.0|255.0] "" Vector__XXX
  SG_ sig_28_30 : 28|30@1+ (1.0000000000000006E-5,3162.2776601683795) [3162.2776601683795|13899.695880168387] "kWh" Vector__XXX
  SG_ sig_15_15 : 15|15@0+ (1.0000000000000011E-10,3.162277660168379E-6) [3.162277660168379E-6|6.438877660168383E-6] "km/h" Vector__XXX
  SG_ sig_16_1 : 16|1@0+ (1.0,0.0) [0.0|1.0] "" Vector__XXX
  SG_ sig_27_4 : 27|4@0+ (1000.0,-3162.2776601683795) [-3162.2776601683795|10837.72233983162] "A" Vector__XXX
  SG_ sig_63_2 : 63|2@0+ (1.0,0.0) [0.0|3.0] "" Vector__XXX

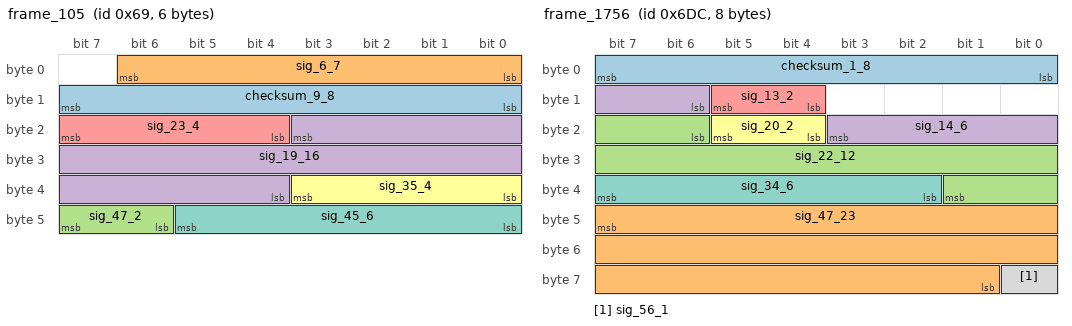
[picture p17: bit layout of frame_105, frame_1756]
BO_ 105 frame_105: 6 Vector__XXX
  SG_ checksum_9_8 : 15|8@0+ (1.0,0.0) [0.0|255.0] "" ECU
  SG_ sig_6_7 : 6|7@0+ (1.0,0.0) [0.0|126.0] "" ECU
  SG_ sig_47_2 : 47|2@0- (1.0,0.0) [-2.0|1.0] "" ECU
  SG_ sig_19_16 : 19|16@0+ (1.0,0.0) [0.0|65534.0] "" ECU
  SG_ sig_23_4 : 23|4@0+ (0.1,-0.31622776601683794) [-0.31622776601683794|1.0837722339831621] "m/s^2" ECU
  SG_ sig_35_4 : 35|4@0- (1.0000000000000005E-4,-3.1622776601683794E-4) [-0.0011162277660168383|2.8377223398316233E-4] "W" ECU
  SG_ sig_45_6 : 45|6@0- (1.0000000000000006E-5,-3.1622776601683794E-4) [-6.362277660168381E-4|-1.622776601683775E-5] "A" ECU

BO_ 1756 frame_1756: 8 Vector__XXX
  SG_ checksum_1_8 : 7|8@0+ (1.0,0.0) [0.0|255.0] "" ECU
  SG_ sig_47_23 : 47|23@0+ (1.0000000000000007E-7,0.0) [0.0|0.8388606000000006] "V" ECU
  SG_ sig_22_12 : 22|12@1+ (1.0000000000000006E-6,0.0031622776601683794) [0.0031622776601683794|0.007256277660168382] "A" ECU
  SG_ sig_14_6 : 14|6@1- (10.0,0.0) [-320.0|300.0] "kWh" ECU
  SG_ sig_13_2 : 13|2@0+ (1.0,0.0) [0.0|3.0] "" ECU
  SG_ sig_20_2 : 20|2@1+ (1.0,0.0) [0.0|3.0] "" ECU
  SG_ sig_34_6 : 34|6@1+ (100.0,3162.2776601683795) [3162.2776601683795|9362.27766016838] "m/s^2" ECU
  SG_ sig_56_1 : 56|1@1+ (1.0,0.0) [0.0|1.0] "" ECU

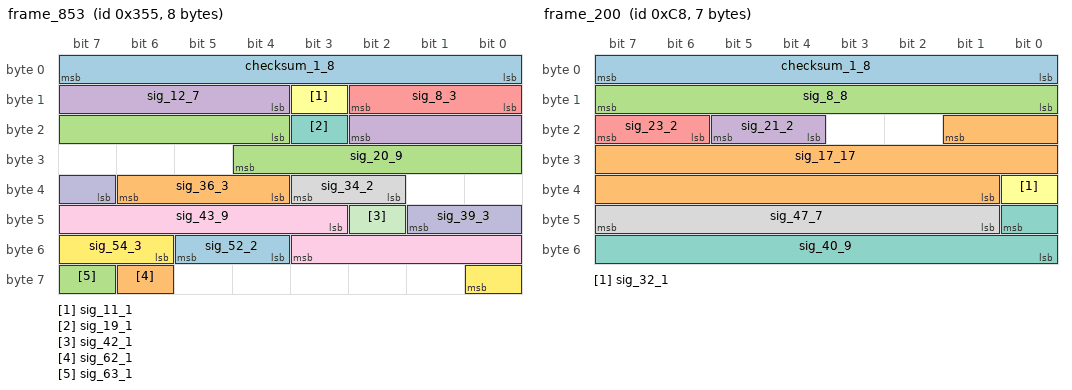
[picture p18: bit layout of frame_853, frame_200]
BO_ 853 frame_853: 8 ECU
  SG_ checksum_1_8 : 0|8@1+ (1.0,0.0) [0.0|255.0] "" Vector__XXX
  SG_ sig_36_3 : 36|3@1+ (1.0,0.0) [0.0|6.0] "" Vector__XXX
  SG_ sig_20_9 : 20|9@1+ (1.0,0.0) [0.0|510.0] "" Vector__XXX
  SG_ sig_12_7 : 12|7@1+ (1.0,0.0) [0.0|126.0] "" Vector__XXX
  SG_ sig_8_3 : 8|3@1- (1.0,0.0) [-4.0|2.0] "" Vector__XXX
  SG_ sig_11_1 : 11|1@1+ (1.0,0.0) [0.0|1.0] "" Vector__XXX
  SG_ sig_19_1 : 19|1@1+ (1.0,0.0) [0.0|1.0] "" Vector__XXX
  SG_ sig_34_2 : 34|2@1- (1.0,0.0) [-2.0|1.0] "" Vector__XXX
  SG_ sig_43_9 : 43|9@1- (1.0,0.0) [-256.0|254.0] "" Vector__XXX
  SG_ sig_39_3 : 39|3@1+ (1.0,0.0) [0.0|6.0] "" Vector__XXX
  SG_ sig_42_1 : 42|1@1+ (1.0,0.0) [0.0|1.0] "" Vector__XXX
  SG_ sig_54_3 : 54|3@1+ (1.0,0.0) [0.0|6.0] "" Vector__XXX
  SG_ sig_52_2 : 52|2@1- (1.0,0.0) [-2.0|1.0] "" Vector__XXX
  SG_ sig_62_1 : 62|1@1+ (1.0,0.0) [0.0|1.0] "" Vector__XXX
  SG_ sig_63_1 : 63|1@1+ (1.0,0.0) [0.0|1.0] "" Vector__XXX

BO_ 988 frame_988: 6 Vector__XXX
  SG_ checksum_41_8 : 47|8@0+ (1.0,0.0) [0.0|255.0] "" ECU
  SG_ sig_8_20 : 8|20@1- (1.0,0.0) [-524288.0|524286.0] "" ECU
  SG_ sig_7_7 : 7|7@0- (1.0000000000000005E-4,0.0) [-0.006400000000000003|0.006200000000000002] "s" ECU
  SG_ sig_31_4 : 31|4@0- (1.0000000000000006E-5,0.0) [-8.000000000000005E-5|6.0000000000000035E-5] "s" ECU
  SG_ sig_32_8 : 32|8@1- (0.010000000000000002,0.31622776601683794) [-0.9637722339831623|1.5762277660168382] "m/s^2" ECU

BO_ 200 frame_200: 7 Vector__XXX
  SG_ checksum_1_8 : 0|8@1+ (1.0,0.0) [0.0|255.0] "" ECU
  SG_ sig_17_17 : 17|17@0- (1.0,0.0) [-65536.0|65534.0] "" ECU
  SG_ sig_8_8 : 8|8@1+ (1.0000000000000006E-6,3.1622776601683795E-5) [3.1622776601683795E-5|2.8562277660168397E-4] "W" ECU
  SG_ sig_21_2 : 21|2@0+ (1.0,0.0) [0.0|3.0] "" ECU
  SG_ sig_23_2 : 23|2@0- (1.0,0.0) [-2.0|1.0] "" ECU
  SG_ sig_32_1 : 32|1@1+ (1.0,0.0) [0.0|1.0] "" ECU
  SG_ sig_40_9 : 40|9@0+ (1.0,0.0) [0.0|510.0] "" ECU
  SG_ sig_47_7 : 47|7@0- (1.0,0.0) [-64.0|62.0] "" ECU

BO_ 2 frame_2: 5 Vector__XXX
  SG_ checksum_17_8 : 16|8@1+ (1.0,0.0) [0.0|255.0] "" ECU
  SG_ sig_1_12 : 1|12@1+ (1.0,0.0) [0.0|4094.0] "" ECU
  SG_ sig_0_1 : 0|1@1+ (1.0,0.0) [0.0|1.0] "" ECU
  SG_ sig_15_2 : 15|2@0- (1.0,0.0) [-2.0|1.0] "" ECU
  SG_ sig_13_1 : 13|1@0+ (1.0,0.0) [0.0|1.0] "" ECU
  SG_ sig_24_16 : 24|16@1+ (1.0,0.0) [0.0|65534.0] "" ECU

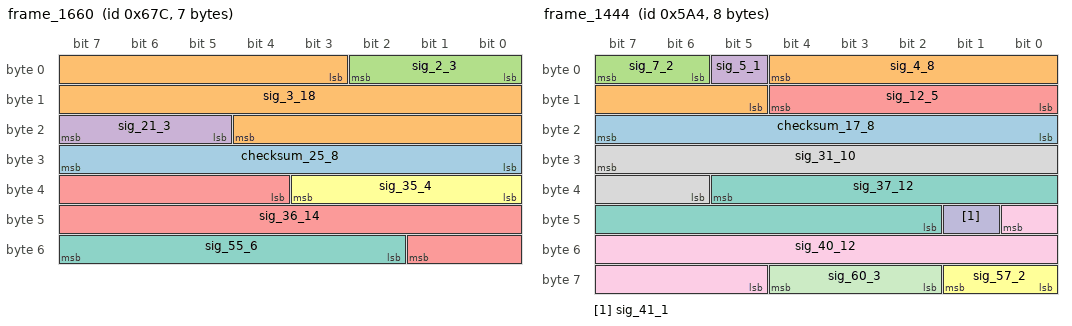
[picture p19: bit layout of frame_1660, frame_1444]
BO_ 1660 frame_1660: 7 Vector__XXX
  SG_ checksum_25_8 : 31|8@0+ (1.0,0.0) [0.0|255.0] "" ECU
  SG_ sig_3_18 : 3|18@1- (1.0,0.0) [-131072.0|131070.0] "" ECU
  SG_ sig_2_3 : 2|3@0- (1.0,0.0) [-4.0|2.0] "" ECU
  SG_ sig_21_3 : 21|3@1+ (1.0,0.0) [0.0|6.0] "" ECU
  SG_ sig_36_14 : 36|14@1+ (1.0,0.0) [0.0|16382.0] "" ECU
  SG_ sig_35_4 : 35|4@0- (1.0000000000000006E-6,3.162277660168379E-6) [-4.8377223398316255E-6|9.162277660168383E-6] "kWh" ECU
  SG_ sig_55_6 : 55|6@0- (0.010000000000000002,0.0) [-0.32000000000000006|0.30000000000000004] "km/h" ECU

BO_ 1875 frame_1875: 6 Vector__XXX
  SG_ checksum_17_8 : 16|8@1+ (1.0,0.0) [0.0|255.0] "" ECU
  SG_ sig_7_16 : 7|16@0+ (1.0,0.0) [0.0|65534.0] "" ECU
  SG_ sig_30_17 : 30|17@1- (1.0000000000000006E-6,0.0) [-0.06553600000000004|0.06553400000000004] "s" ECU
  SG_ sig_29_6 : 29|6@0+ (1.0,0.0) [0.0|62.0] "" ECU
  SG_ sig_47_1 : 47|1@0+ (1.0,0.0) [0.0|1.0] "" ECU

BO_ 1444 frame_1444: 8 ECU
  SG_ checksum_17_8 : 23|8@0+ (1.0,0.0) [0.0|255.0] "" Vector__XXX
  SG_ sig_4_8 : 4|8@0- (0.010000000000000002,-0.31622776601683794) [-1.5962277660168382|0.9437722339831622] "s" Vector__XXX
  SG_ sig_7_2 : 7|2@0+ (1.0,0.0) [0.0|3.0] "" Vector__XXX
  SG_ sig_5_1 : 5|1@0+ (1.0,0.0) [0.0|1.0] "" Vector__XXX
  SG_ sig_12_5 : 12|5@0- (1000.0,0.0) [-16000.0|14000.0] "W" Vector__XXX
  SG_ sig_57_2 : 57|2@0+ (1.0,0.0) [0.0|3.0] "" Vector__XXX
  SG_ sig_37_12 : 37|12@0- (1.0,0.0) [-2048.0|2046.0] "" Vector__XXX
  SG_ sig_31_10 : 31|10@0+ (1.0,316.22776601683796) [316.22776601683796|1338.227766016838] "V" Vector__XXX
  SG_ sig_40_12 : 40|12@0+ (1.0000000000000006E-6,-0.0031622776601683794) [-0.0031622776601683794|9.317223398316228E-4] "kWh" Vector__XXX
  SG_ sig_41_1 : 41|1@0+ (1.0,0.0) [0.0|1.0] "" Vector__XXX
  SG_ sig_60_3 : 60|3@0- (1.0,0.0) [-4.0|2.0] "" Vector__XXX

CM_ BO_ 577 "Randomly defined CAN frame";
CM_ SG_ 577 checksum_9_8 "8 Bit checksum for protection of frame contents";
CM_ BO_ 517 "Randomly defined CAN frame";
CM_ SG_ 517 checksum_9_8 "8 Bit checksum for protection of frame contents";
CM_ BO_ 1470 "Randomly defined CAN frame";
CM_ SG_ 1470 checksum_25_8 "8 Bit checksum for protection of frame contents";
CM_ BO_ 1189 "Randomly defined CAN frame";
CM_ SG_ 1189 checksum_49_8 "8 Bit checksum for protection of frame contents";
CM_ BO_ 1801 "Randomly defined CAN frame";
CM_ SG_ 1801 checksum_25_8 "8 Bit checksum for protection of frame contents";
CM_ BO_ 1926 "Randomly defined CAN frame";
CM_ SG_ 1926 checksum_1_8 "8 Bit checksum for protection of frame contents";
CM_ BO_ 986 "Randomly defined CAN frame";
CM_ SG_ 986 checksum_1_8 "8 Bit checksum for protection of frame contents";
CM_ BO_ 998 "Randomly defined CAN frame";
CM_ SG_ 998 checksum_33_8 "8 Bit checksum for protection of frame contents";
CM_ BO_ 480 "Randomly defined CAN frame";
CM_ SG_ 480 checksum_25_8 "8 Bit checksum for protection of frame contents";
CM_ BO_ 865 "Randomly defined CAN frame";
CM_ SG_ 865 checksum_41_8 "8 Bit checksum for protection of frame contents";
CM_ BO_ 743 "Randomly defined CAN frame";
CM_ SG_ 743 checksum_9_8 "8 Bit checksum for protection of frame contents";
CM_ BO_ 1940 "Randomly defined CAN frame";
CM_ SG_ 1940 checksum_9_8 "8 Bit checksum for protection of frame contents";
CM_ BO_ 764 "Randomly defined CAN frame";
CM_ SG_ 764 checksum_25_8 "8 Bit checksum for protection of frame contents";
CM_ BO_ 907 "Randomly defined CAN frame";
CM_ SG_ 907 checksum_9_8 "8 Bit checksum for protection of frame contents";
CM_ BO_ 366 "Randomly defined CAN frame";
CM_ SG_ 366 checksum_17_8 "8 Bit checksum for protection of frame contents";
CM_ BO_ 2039 "Randomly defined CAN frame";
CM_ SG_ 2039 checksum_25_8 "8 Bit checksum for protection of frame contents";
CM_ BO_ 411 "Randomly defined CAN frame";
CM_ SG_ 411 checksum_17_8 "8 Bit checksum for protection of frame contents";
CM_ BO_ 376 "Randomly defined CAN frame";
CM_ SG_ 376 checksum_41_8 "8 Bit checksum for protection of frame contents";
CM_ BO_ 655 "Randomly defined CAN frame";
CM_ SG_ 655 checksum_25_8 "8 Bit checksum for protection of frame contents";
CM_ BO_ 1985 "Randomly defined CAN frame";
CM_ SG_ 1985 checksum_1_8 "8 Bit checksum for protection of frame contents";
CM_ BO_ 1572 "Randomly defined CAN frame";
CM_ SG_ 1572 checksum_1_8 "8 Bit checksum for protection of frame contents";
CM_ BO_ 253 "Randomly defined CAN frame";
CM_ SG_ 253 checksum_41_8 "8 Bit checksum for protection of frame contents";
CM_ BO_ 866 "Randomly defined CAN frame";
CM_ SG_ 866 checksum_25_8 "8 Bit checksum for protection of frame contents";
CM_ BO_ 1332 "Randomly defined CAN frame";
CM_ SG_ 1332 checksum_49_8 "8 Bit checksum for protection of frame contents";
CM_ BO_ 86 "Randomly defined CAN frame";
CM_ SG_ 86 checksum_9_8 "8 Bit checksum for protection of frame contents";
CM_ BO_ 1270 "Randomly defined CAN frame";
CM_ SG_ 1270 checksum_1_8 "8 Bit checksum for protection of frame contents";
CM_ BO_ 1002 "Randomly defined CAN frame";
CM_ SG_ 1002 checksum_1_8 "8 Bit checksum for protection of frame contents";
CM_ BO_ 1957 "Randomly defined CAN frame";
CM_ SG_ 1957 checksum_41_8 "8 Bit checksum for protection of frame contents";
CM_ BO_ 969 "Randomly defined CAN frame";
CM_ SG_ 969 checksum_49_8 "8 Bit checksum for protection of frame contents";
CM_ BO_ 1631 "Randomly defined CAN frame";
CM_ SG_ 1631 checksum_17_8 "8 Bit checksum for protection of frame contents";
CM_ BO_ 823 "Randomly defined CAN frame";
CM_ SG_ 823 checksum_41_8 "8 Bit checksum for protection of frame contents";
CM_ BO_ 83 "Randomly defined CAN frame";
CM_ SG_ 83 checksum_41_8 "8 Bit checksum for protection of frame contents";
CM_ BO_ 481 "Randomly defined CAN frame";
CM_ SG_ 481 checksum_33_8 "8 Bit checksum for protection of frame contents";
CM_ BO_ 739 "Randomly defined CAN frame";
CM_ SG_ 739 checksum_41_8 "8 Bit checksum for protection of frame contents";
CM_ BO_ 65 "Randomly defined CAN frame";
CM_ SG_ 65 checksum_9_8 "8 Bit checksum for protection of frame contents";
CM_ BO_ 1776 "Randomly defined CAN frame";
CM_ SG_ 1776 checksum_1_8 "8 Bit checksum for protection of frame contents";
CM_ BO_ 11 "Randomly defined CAN frame";
CM_ SG_ 11 checksum_17_8 "8 Bit checksum for protection of frame contents";
CM_ BO_ 484 "Randomly defined CAN frame";
CM_ SG_ 484 checksum_17_8 "8 Bit checksum for protection of frame contents";
CM_ BO_ 1970 "Randomly defined CAN frame";
CM_ SG_ 1970 checksum_1_8 "8 Bit checksum for protection of frame contents";
CM_ BO_ 732 "Randomly defined CAN frame";
CM_ SG_ 732 checksum_17_8 "8 Bit checksum for protection of frame contents";
CM_ BO_ 682 "Randomly defined CAN frame";
CM_ SG_ 682 checksum_17_8 "8 Bit checksum for protection of frame contents";
CM_ BO_ 1840 "Randomly defined CAN frame";
CM_ SG_ 1840 checksum_33_8 "8 Bit checksum for protection of frame contents";
CM_ BO_ 2036 "Randomly defined CAN frame";
CM_ SG_ 2036 checksum_17_8 "8 Bit checksum for protection of frame contents";
CM_ BO_ 163 "Randomly defined CAN frame";
CM_ SG_ 163 checksum_25_8 "8 Bit checksum for protection of frame contents";
CM_ BO_ 963 "Randomly defined CAN frame";
CM_ SG_ 963 checksum_25_8 "8 Bit checksum for protection of frame contents";
CM_ BO_ 510 "Randomly defined CAN frame";
CM_ SG_ 510 checksum_9_8 "8 Bit checksum for protection of frame contents";
CM_ BO_ 948 "Randomly defined CAN frame";
CM_ SG_ 948 checksum_1_8 "8 Bit checksum for protection of frame contents";
CM_ BO_ 105 "Randomly defined CAN frame";
CM_ SG_ 105 checksum_9_8 "8 Bit checksum for protection of frame contents";
CM_ BO_ 1756 "Randomly defined CAN frame";
CM_ SG_ 1756 checksum_1_8 "8 Bit checksum for protection of frame contents";
CM_ BO_ 853 "Randomly defined CAN frame";
CM_ SG_ 853 checksum_1_8 "8 Bit checksum for protection of frame contents";
CM_ BO_ 988 "Randomly defined CAN frame";
CM_ SG_ 988 checksum_41_8 "8 Bit checksum for protection of frame contents";
CM_ BO_ 200 "Randomly defined CAN frame";
CM_ SG_ 200 checksum_1_8 "8 Bit checksum for protection of frame contents";
CM_ BO_ 2 "Randomly defined CAN frame";
CM_ SG_ 2 checksum_17_8 "8 Bit checksum for protection of frame contents";
CM_ BO_ 1660 "Randomly defined CAN frame";
CM_ SG_ 1660 checksum_25_8 "8 Bit checksum for protection of frame contents";
CM_ BO_ 1875 "Randomly defined CAN frame";
CM_ SG_ 1875 checksum_17_8 "8 Bit checksum for protection of frame contents";
CM_ BO_ 1444 "Randomly defined CAN frame";
CM_ SG_ 1444 checksum_17_8 "8 Bit checksum for protection of frame contents";
BA_DEF_ "Author" STRING;
BA_DEF_ BO_ "frameSendMode" ENUM  "regular","event","mixed";
BA_DEF_ BO_ "sendPeriod" INT 5 10000;
BA_DEF_ BO_ "crcStartValue" INT 1 255;
BA_DEF_ BO_ "eventMinDistance" INT 5 10000;
BA_DEF_ SG_ "initialValue" FLOAT -1e38 1e38;
BA_DEF_DEF_ "Author" "http://sourceforge.net/projects/comframe/";
BA_DEF_DEF_ "frameSendMode" "regular";
BA_DEF_DEF_ "sendPeriod" 10;
BA_DEF_DEF_ "crcStartValue" 1;
BA_DEF_DEF_ "eventMinDistance" 10;
BA_DEF_DEF_ "initialValue" 0.0;
BA_ "sendPeriod" BO_ 577 500;
BA_ "crcStartValue" BO_ 577 106;
BA_ "sendPeriod" BO_ 517 20;
BA_ "crcStartValue" BO_ 517 240;
BA_ "initialValue" SG_ 517 sig_0_8 22.0;
BA_ "initialValue" SG_ 517 sig_22_18 -6646.0;
BA_ "initialValue" SG_ 517 sig_16_6 -7.0;
BA_ "initialValue" SG_ 517 sig_41_7 0.6600000000000001;
BA_ "initialValue" SG_ 517 sig_40_1 1.0;
BA_ "initialValue" SG_ 517 sig_48_8 -2.7;
BA_ "sendPeriod" BO_ 1470 50;
BA_ "crcStartValue" BO_ 1470 74;
BA_ "initialValue" SG_ 1470 sig_4_12 1779.0;
BA_ "initialValue" SG_ 1470 sig_23_6 42000.0;
BA_ "sendPeriod" BO_ 1189 50;
BA_ "crcStartValue" BO_ 1189 134;
BA_ "initialValue" SG_ 1189 sig_29_22 -8.67303660168376E-7;
BA_ "initialValue" SG_ 1189 sig_3_20 -516865.0;
BA_ "initialValue" SG_ 1189 sig_63_8 8.937722339831628E-5;
BA_ "sendPeriod" BO_ 1801 100;
BA_ "crcStartValue" BO_ 1801 89;
BA_ "initialValue" SG_ 1801 sig_0_16 11661.0;
BA_ "initialValue" SG_ 1801 sig_6_6 47.622776601683796;
BA_ "initialValue" SG_ 1801 sig_40_14 10.16127766016838;
BA_ "initialValue" SG_ 1801 sig_33_9 5.000000000000004E-6;
BA_ "initialValue" SG_ 1801 sig_39_6 5.622776601683774E-7;
BA_ "initialValue" SG_ 1801 sig_58_2 -1.0;
BA_ "initialValue" SG_ 1801 sig_56_1 1.0;
BA_ "sendPeriod" BO_ 1926 100;
BA_ "crcStartValue" BO_ 1926 20;
BA_ "initialValue" SG_ 1926 sig_17_10 0.04290000000000002;
BA_ "initialValue" SG_ 1926 sig_9_5 28.0;
BA_ "initialValue" SG_ 1926 sig_8_1 1.0;
BA_ "initialValue" SG_ 1926 sig_15_2 1.0;
BA_ "initialValue" SG_ 1926 sig_16_6 -9.000000000000005E-5;
BA_ "initialValue" SG_ 1926 sig_37_10 4.0322776601683803E-5;
BA_ "initialValue" SG_ 1926 sig_32_5 1.0000000000000006E-5;
BA_ "initialValue" SG_ 1926 sig_48_15 28.41277660168379;
BA_ "sendPeriod" BO_ 986 5;
BA_ "crcStartValue" BO_ 986 248;
BA_ "initialValue" SG_ 986 sig_36_21 9611.927660168381;
BA_ "initialValue" SG_ 986 sig_15_6 -3.0;
BA_ "initialValue" SG_ 986 sig_14_9 -254.0;
BA_ "initialValue" SG_ 986 sig_30_7 -1.5377223398316236E-5;
BA_ "initialValue" SG_ 986 sig_34_3 2.0;
BA_ "initialValue" SG_ 986 sig_63_7 0.017000000000000005;
BA_ "frameSendMode" BO_ 998 2;
BA_ "sendPeriod" BO_ 998 10000;
BA_ "eventMinDistance" BO_ 998 50;
BA_ "crcStartValue" BO_ 998 150;
BA_ "initialValue" SG_ 998 sig_8_13 -52502.77660168379;
BA_ "initialValue" SG_ 998 sig_0_8 21.0;
BA_ "initialValue" SG_ 998 sig_15_5 3.76227766016838E-4;
BA_ "initialValue" SG_ 998 sig_9_2 3.0;
BA_ "initialValue" SG_ 998 sig_26_3 3.0;
BA_ "initialValue" SG_ 998 sig_47_16 152.07000000000002;
BA_ "initialValue" SG_ 998 sig_46_5 -0.002762277660168379;
BA_ "initialValue" SG_ 998 sig_40_2 1.0;
BA_ "frameSendMode" BO_ 480 2;
BA_ "sendPeriod" BO_ 480 50;
BA_ "eventMinDistance" BO_ 480 50;
BA_ "crcStartValue" BO_ 480 21;
BA_ "initialValue" SG_ 480 sig_0_6 61.0;
BA_ "initialValue" SG_ 480 sig_9_15 1.6941000000000008;
BA_ "initialValue" SG_ 480 sig_7_2 1.0;
BA_ "initialValue" SG_ 480 sig_6_1 1.0;
BA_ "initialValue" SG_ 480 sig_32_7 11.46227766016838;
BA_ "initialValue" SG_ 480 sig_50_13 -2881.0;
BA_ "initialValue" SG_ 480 sig_47_6 62.0;
BA_ "initialValue" SG_ 480 sig_40_2 -2.0;
BA_ "initialValue" SG_ 480 sig_49_3 -1.0;
BA_ "sendPeriod" BO_ 865 1000;
BA_ "crcStartValue" BO_ 865 28;
BA_ "initialValue" SG_ 865 sig_23_2 1.0;
BA_ "initialValue" SG_ 865 sig_2_16 0.004529776601683775;
BA_ "initialValue" SG_ 865 sig_21_3 3.0;
BA_ "initialValue" SG_ 865 sig_28_4 9837.72233983162;
BA_ "initialValue" SG_ 865 sig_39_7 -2.0622776601683794;
BA_ "sendPeriod" BO_ 743 1000;
BA_ "crcStartValue" BO_ 743 103;
BA_ "initialValue" SG_ 743 sig_22_12 2136.0;
BA_ "initialValue" SG_ 743 sig_20_5 51.622776601683796;
BA_ "initialValue" SG_ 743 sig_21_1 1.0;
BA_ "initialValue" SG_ 743 sig_39_6 35.0;
BA_ "sendPeriod" BO_ 1940 10000;
BA_ "crcStartValue" BO_ 1940 233;
BA_ "initialValue" SG_ 1940 sig_7_8 5762.27766016838;
BA_ "initialValue" SG_ 1940 sig_20_15 0.2471677660168379;
BA_ "initialValue" SG_ 1940 sig_16_4 -8.377223398316232E-7;
BA_ "initialValue" SG_ 1940 sig_39_4 6162.27766016838;
BA_ "initialValue" SG_ 1940 sig_43_5 376.22776601683796;
BA_ "initialValue" SG_ 1940 sig_40_2 3.0;
BA_ "sendPeriod" BO_ 764 20;
BA_ "crcStartValue" BO_ 764 196;
BA_ "initialValue" SG_ 764 sig_11_7 -1.1622776601683782E-4;
BA_ "initialValue" SG_ 764 sig_0_8 -6.22776601683782E-5;
BA_ "initialValue" SG_ 764 sig_8_2 1.0;
BA_ "initialValue" SG_ 764 sig_19_5 1.0;
BA_ "initialValue" SG_ 764 sig_38_7 -2437.7223398316205;
BA_ "initialValue" SG_ 764 sig_46_2 -1.0;
BA_ "frameSendMode" BO_ 907 2;
BA_ "sendPeriod" BO_ 907 10000;
BA_ "eventMinDistance" BO_ 907 100;
BA_ "crcStartValue" BO_ 907 97;
BA_ "initialValue" SG_ 907 sig_7_7 8.662277660168382E-5;
BA_ "initialValue" SG_ 907 sig_20_17 -1516.7223398316205;
BA_ "initialValue" SG_ 907 sig_21_3 2.0;
BA_ "initialValue" SG_ 907 sig_34_10 509.0;
BA_ "initialValue" SG_ 907 sig_35_1 1.0;
BA_ "initialValue" SG_ 907 sig_40_1 1.0;
BA_ "sendPeriod" BO_ 366 25;
BA_ "crcStartValue" BO_ 366 249;
BA_ "initialValue" SG_ 366 sig_10_2 -2.0;
BA_ "initialValue" SG_ 366 sig_6_9 -34.0;
BA_ "initialValue" SG_ 366 sig_7_1 1.0;
BA_ "initialValue" SG_ 366 sig_13_2 1.0;
BA_ "initialValue" SG_ 366 sig_11_1 1.0;
BA_ "initialValue" SG_ 366 sig_8_1 1.0;
BA_ "initialValue" SG_ 366 sig_35_12 0.08047223398316222;
BA_ "initialValue" SG_ 366 sig_24_5 4.16227766016838E-6;
BA_ "frameSendMode" BO_ 2039 2;
BA_ "sendPeriod" BO_ 2039 500;
BA_ "eventMinDistance" BO_ 2039 50;
BA_ "crcStartValue" BO_ 2039 202;
BA_ "initialValue" SG_ 2039 sig_2_9 -123.0;
BA_ "initialValue" SG_ 2039 sig_7_5 47622.77660168379;
BA_ "initialValue" SG_ 2039 sig_22_7 0.6462277660168381;
BA_ "initialValue" SG_ 2039 sig_32_23 10425.367660168382;
BA_ "initialValue" SG_ 2039 sig_39_7 62.0;
BA_ "initialValue" SG_ 2039 sig_57_2 3.0;
BA_ "frameSendMode" BO_ 411 2;
BA_ "sendPeriod" BO_ 411 100;
BA_ "eventMinDistance" BO_ 411 100;
BA_ "crcStartValue" BO_ 411 3;
BA_ "initialValue" SG_ 411 sig_2_14 -27517.223398316208;
BA_ "initialValue" SG_ 411 sig_1_2 1.0;
BA_ "initialValue" SG_ 411 sig_26_10 -30200.0;
BA_ "initialValue" SG_ 411 sig_38_3 4.0;
BA_ "initialValue" SG_ 411 sig_25_3 1.0;
BA_ "sendPeriod" BO_ 376 20;
BA_ "crcStartValue" BO_ 376 253;
BA_ "initialValue" SG_ 376 sig_5_15 -0.0016670776601683782;
BA_ "initialValue" SG_ 376 sig_6_1 1.0;
BA_ "initialValue" SG_ 376 sig_21_15 1.9040000000000016E-4;
BA_ "initialValue" SG_ 376 sig_33_5 -0.02262277660168379;
BA_ "initialValue" SG_ 376 sig_49_11 -1017.7223398316205;
BA_ "initialValue" SG_ 376 sig_63_4 -0.0616227766016838;
BA_ "initialValue" SG_ 376 sig_48_1 1.0;
BA_ "sendPeriod" BO_ 655 100;
BA_ "crcStartValue" BO_ 655 81;
BA_ "initialValue" SG_ 655 sig_6_10 308.0;
BA_ "initialValue" SG_ 655 sig_11_12 3765.0;
BA_ "initialValue" SG_ 655 sig_12_1 1.0;
BA_ "initialValue" SG_ 655 sig_39_8 -1.3362277660168387E-5;
BA_ "sendPeriod" BO_ 1985 50;
BA_ "crcStartValue" BO_ 1985 32;
BA_ "initialValue" SG_ 1985 sig_26_15 -4.18187766016838E-6;
BA_ "initialValue" SG_ 1985 sig_9_13 -2573.0;
BA_ "initialValue" SG_ 1985 sig_8_3 -4.0;
BA_ "initialValue" SG_ 1985 sig_24_2 3.0;
BA_ "initialValue" SG_ 1985 sig_41_6 -6.0;
BA_ "initialValue" SG_ 1985 sig_47_1 1.0;
BA_ "sendPeriod" BO_ 1572 100;
BA_ "crcStartValue" BO_ 1572 118;
BA_ "sendPeriod" BO_ 253 10000;
BA_ "crcStartValue" BO_ 253 144;
BA_ "initialValue" SG_ 253 sig_9_3 -1.0;
BA_ "initialValue" SG_ 253 sig_4_5 2.862277660168379E-4;
BA_ "initialValue" SG_ 253 sig_1_3 -1.0;
BA_ "initialValue" SG_ 253 sig_0_1 1.0;
BA_ "initialValue" SG_ 253 sig_20_6 0.5;
BA_ "initialValue" SG_ 253 sig_27_9 459.0;
BA_ "initialValue" SG_ 253 sig_26_1 1.0;
BA_ "initialValue" SG_ 253 sig_36_4 -5.0;
BA_ "sendPeriod" BO_ 866 100;
BA_ "crcStartValue" BO_ 866 93;
BA_ "initialValue" SG_ 866 sig_5_7 -15.0;
BA_ "initialValue" SG_ 866 sig_0_2 -1.0;
BA_ "initialValue" SG_ 866 sig_15_6 -24622.776601683792;
BA_ "initialValue" SG_ 866 sig_14_3 -3.0;
BA_ "initialValue" SG_ 866 sig_21_3 2.0;
BA_ "initialValue" SG_ 866 sig_47_8 54.0;
BA_ "initialValue" SG_ 866 sig_39_8 137.0;
BA_ "sendPeriod" BO_ 1332 5;
BA_ "crcStartValue" BO_ 1332 66;
BA_ "initialValue" SG_ 1332 sig_15_23 -2.6407060000000028E-5;
BA_ "initialValue" SG_ 1332 sig_2_9 -13.0;
BA_ "initialValue" SG_ 1332 sig_1_2 -2.0;
BA_ "initialValue" SG_ 1332 sig_14_4 -2.0;
BA_ "initialValue" SG_ 1332 sig_39_1 1.0;
BA_ "initialValue" SG_ 1332 sig_62_7 2.5000000000000017E-4;
BA_ "sendPeriod" BO_ 86 100;
BA_ "crcStartValue" BO_ 86 233;
BA_ "initialValue" SG_ 86 sig_1_5 4162.27766016838;
BA_ "initialValue" SG_ 86 sig_6_2 1.0;
BA_ "initialValue" SG_ 86 sig_18_13 3750.0;
BA_ "initialValue" SG_ 86 sig_16_2 3.0;
BA_ "initialValue" SG_ 86 sig_31_8 201.0;
BA_ "initialValue" SG_ 86 sig_39_1 1.0;
BA_ "sendPeriod" BO_ 1270 20;
BA_ "crcStartValue" BO_ 1270 130;
BA_ "initialValue" SG_ 1270 sig_31_15 11105.0;
BA_ "initialValue" SG_ 1270 sig_14_15 306.4700000000001;
BA_ "initialValue" SG_ 1270 sig_8_6 1377.2233983162077;
BA_ "initialValue" SG_ 1270 sig_47_1 1.0;
BA_ "initialValue" SG_ 1270 sig_46_1 1.0;
BA_ "sendPeriod" BO_ 1002 50;
BA_ "crcStartValue" BO_ 1002 64;
BA_ "initialValue" SG_ 1002 sig_32_9 241.0;
BA_ "initialValue" SG_ 1002 sig_14_18 106923.0;
BA_ "initialValue" SG_ 1002 sig_25_3 4.0;
BA_ "initialValue" SG_ 1002 sig_24_7 -0.002462277660168379;
BA_ "initialValue" SG_ 1002 sig_33_1 1.0;
BA_ "crcStartValue" BO_ 1957 61;
BA_ "initialValue" SG_ 1957 sig_30_15 28.900000000000006;
BA_ "initialValue" SG_ 1957 sig_4_17 0.7416677660168383;
BA_ "initialValue" SG_ 1957 sig_7_3 3.0;
BA_ "initialValue" SG_ 1957 sig_19_5 7.0;
BA_ "sendPeriod" BO_ 969 1000;
BA_ "crcStartValue" BO_ 969 244;
BA_ "initialValue" SG_ 969 sig_13_25 -1.5675801601683776E-4;
BA_ "initialValue" SG_ 969 sig_1_5 -6.0;
BA_ "initialValue" SG_ 969 sig_7_2 2.0;
BA_ "initialValue" SG_ 969 sig_32_3 1.0;
BA_ "initialValue" SG_ 969 sig_36_2 -2.0;
BA_ "initialValue" SG_ 969 sig_47_7 59.0;
BA_ "initialValue" SG_ 969 sig_56_7 -6300.0;
BA_ "sendPeriod" BO_ 1631 1000;
BA_ "crcStartValue" BO_ 1631 132;
BA_ "initialValue" SG_ 1631 sig_0_16 585.507766016838;
BA_ "initialValue" SG_ 1631 sig_35_9 186.0;
BA_ "initialValue" SG_ 1631 sig_28_9 43322.77660168379;
BA_ "initialValue" SG_ 1631 sig_30_2 1.0;
BA_ "initialValue" SG_ 1631 sig_40_8 207000.0;
BA_ "initialValue" SG_ 1631 sig_41_2 3.0;
BA_ "frameSendMode" BO_ 823 2;
BA_ "sendPeriod" BO_ 823 10000;
BA_ "eventMinDistance" BO_ 823 1000;
BA_ "crcStartValue" BO_ 823 99;
BA_ "initialValue" SG_ 823 sig_11_10 0.006060000000000004;
BA_ "initialValue" SG_ 823 sig_0_8 75000.0;
BA_ "initialValue" SG_ 823 sig_14_3 1.0;
BA_ "initialValue" SG_ 823 sig_15_1 1.0;
BA_ "initialValue" SG_ 823 sig_17_18 9.348777660168387E-6;
BA_ "initialValue" SG_ 823 sig_48_8 0.008437722339831626;
BA_ "sendPeriod" BO_ 83 5;
BA_ "crcStartValue" BO_ 83 255;
BA_ "initialValue" SG_ 83 sig_18_16 6409.0;
BA_ "initialValue" SG_ 83 sig_6_20 26909.0;
BA_ "initialValue" SG_ 83 sig_7_1 1.0;
BA_ "initialValue" SG_ 83 sig_34_2 3.0;
BA_ "initialValue" SG_ 83 sig_55_7 -5.0;
BA_ "crcStartValue" BO_ 481 151;
BA_ "initialValue" SG_ 481 sig_7_16 0.5823000000000003;
BA_ "initialValue" SG_ 481 sig_17_15 0.24200776601683788;
BA_ "initialValue" SG_ 481 sig_16_1 1.0;
BA_ "initialValue" SG_ 481 sig_44_17 7.421177660168383E-4;
BA_ "initialValue" SG_ 481 sig_41_3 2.0;
BA_ "initialValue" SG_ 481 sig_40_1 1.0;
BA_ "initialValue" SG_ 481 sig_63_3 5.0;
BA_ "sendPeriod" BO_ 739 10000;
BA_ "crcStartValue" BO_ 739 218;
BA_ "initialValue" SG_ 739 sig_11_23 0.32376820000000023;
BA_ "initialValue" SG_ 739 sig_0_8 -89.0;
BA_ "initialValue" SG_ 739 sig_15_4 41.622776601683796;
BA_ "initialValue" SG_ 739 sig_34_3 1.0;
BA_ "sendPeriod" BO_ 65 500;
BA_ "crcStartValue" BO_ 65 134;
BA_ "initialValue" SG_ 65 sig_6_7 9.700000000000005E-5;
BA_ "initialValue" SG_ 65 sig_7_1 1.0;
BA_ "initialValue" SG_ 65 sig_28_17 8751.0;
BA_ "initialValue" SG_ 65 sig_23_7 -0.0012622776601683785;
BA_ "initialValue" SG_ 65 sig_16_1 1.0;
BA_ "initialValue" SG_ 65 sig_24_4 0.00816227766016838;
BA_ "initialValue" SG_ 65 sig_47_3 -2.0;
BA_ "frameSendMode" BO_ 1776 2;
BA_ "sendPeriod" BO_ 1776 500;
BA_ "eventMinDistance" BO_ 1776 100;
BA_ "crcStartValue" BO_ 1776 69;
BA_ "initialValue" SG_ 1776 sig_15_14 42.0;
BA_ "initialValue" SG_ 1776 sig_30_11 743.0;
BA_ "initialValue" SG_ 1776 sig_16_2 1.0;
BA_ "sendPeriod" BO_ 11 25;
BA_ "crcStartValue" BO_ 11 153;
BA_ "initialValue" SG_ 11 sig_8_8 91.0;
BA_ "initialValue" SG_ 11 sig_7_8 6.762277660168382E-6;
BA_ "initialValue" SG_ 11 sig_24_9 333.0;
BA_ "initialValue" SG_ 11 sig_33_5 16000.0;
BA_ "initialValue" SG_ 11 sig_39_2 -2.0;
BA_ "sendPeriod" BO_ 484 1000;
BA_ "crcStartValue" BO_ 484 178;
BA_ "initialValue" SG_ 484 sig_0_6 56.622776601683796;
BA_ "initialValue" SG_ 484 sig_7_3 -4.0;
BA_ "initialValue" SG_ 484 sig_4_4 -40000.0;
BA_ "initialValue" SG_ 484 sig_10_3 -1.0;
BA_ "sendPeriod" BO_ 1970 5;
BA_ "crcStartValue" BO_ 1970 38;
BA_ "initialValue" SG_ 1970 sig_30_18 0.004624077660168381;
BA_ "initialValue" SG_ 1970 sig_17_5 -4.26227766016838;
BA_ "initialValue" SG_ 1970 sig_15_8 -0.4737722339831622;
BA_ "initialValue" SG_ 1970 sig_16_1 1.0;
BA_ "initialValue" SG_ 1970 sig_40_4 -0.020000000000000004;
BA_ "frameSendMode" BO_ 732 2;
BA_ "sendPeriod" BO_ 732 10000;
BA_ "eventMinDistance" BO_ 732 1000;
BA_ "crcStartValue" BO_ 732 238;
BA_ "initialValue" SG_ 732 sig_7_10 3.540000000000003E-6;
BA_ "initialValue" SG_ 732 sig_10_2 -1.0;
BA_ "initialValue" SG_ 732 sig_12_2 2.0;
BA_ "initialValue" SG_ 732 sig_46_14 7.465000000000005E-4;
BA_ "initialValue" SG_ 732 sig_31_2 2.0;
BA_ "initialValue" SG_ 732 sig_38_6 -31.0;
BA_ "initialValue" SG_ 732 sig_32_2 1.0;
BA_ "initialValue" SG_ 732 sig_48_1 1.0;
BA_ "sendPeriod" BO_ 682 500;
BA_ "crcStartValue" BO_ 682 53;
BA_ "initialValue" SG_ 682 sig_1_9 468.0;
BA_ "initialValue" SG_ 682 sig_14_2 1.0;
BA_ "initialValue" SG_ 682 sig_15_1 1.0;
BA_ "initialValue" SG_ 682 sig_36_14 9063.0;
BA_ "initialValue" SG_ 682 sig_30_10 43822.77660168379;
BA_ "initialValue" SG_ 682 sig_48_6 42.622776601683796;
BA_ "initialValue" SG_ 682 sig_63_8 0.005000000000000001;
BA_ "sendPeriod" BO_ 1840 20;
BA_ "crcStartValue" BO_ 1840 207;
BA_ "initialValue" SG_ 1840 sig_11_15 4.40597766016838;
BA_ "initialValue" SG_ 1840 sig_6_9 -0.022022776601683787;
BA_ "initialValue" SG_ 1840 sig_13_1 1.0;
BA_ "initialValue" SG_ 1840 sig_12_1 1.0;
BA_ "initialValue" SG_ 1840 sig_24_5 1.7622776601683784E-4;
BA_ "initialValue" SG_ 1840 sig_46_11 1.1500000000000001;
BA_ "initialValue" SG_ 1840 sig_47_5 2.162277660168379E-4;
BA_ "initialValue" SG_ 1840 sig_56_8 10600.0;
BA_ "sendPeriod" BO_ 2036 1000;
BA_ "crcStartValue" BO_ 2036 57;
BA_ "initialValue" SG_ 2036 sig_5_11 -1016.0;
BA_ "initialValue" SG_ 2036 sig_42_11 219022.77660168378;
BA_ "initialValue" SG_ 2036 sig_24_14 2458.0;
BA_ "initialValue" SG_ 2036 sig_55_3 -4.0;
BA_ "sendPeriod" BO_ 163 500;
BA_ "crcStartValue" BO_ 163 153;
BA_ "initialValue" SG_ 163 sig_5_9 0.2980000000000001;
BA_ "initialValue" SG_ 163 sig_7_2 -2.0;
BA_ "initialValue" SG_ 163 sig_12_11 360.0;
BA_ "initialValue" SG_ 163 sig_17_2 1.0;
BA_ "initialValue" SG_ 163 sig_38_11 -6.222277660168383E-5;
BA_ "initialValue" SG_ 163 sig_39_5 0.18000000000000005;
BA_ "frameSendMode" BO_ 963 2;
BA_ "sendPeriod" BO_ 963 100;
BA_ "eventMinDistance" BO_ 963 100;
BA_ "crcStartValue" BO_ 963 113;
BA_ "initialValue" SG_ 963 sig_3_18 0.008229422339831628;
BA_ "initialValue" SG_ 963 sig_0_3 6.0;
BA_ "initialValue" SG_ 963 sig_23_1 1.0;
BA_ "initialValue" SG_ 963 sig_32_12 -0.01879000000000001;
BA_ "initialValue" SG_ 963 sig_45_8 8.93772233983163E-6;
BA_ "initialValue" SG_ 963 sig_44_1 1.0;
BA_ "sendPeriod" BO_ 510 50;
BA_ "crcStartValue" BO_ 510 85;
BA_ "initialValue" SG_ 510 sig_2_5 -2.8622776601683793;
BA_ "initialValue" SG_ 510 sig_0_2 2.0;
BA_ "initialValue" SG_ 510 sig_35_17 13612.47766016838;
BA_ "initialValue" SG_ 510 sig_21_11 -1.9977223398316248E-6;
BA_ "initialValue" SG_ 510 sig_16_5 0.38622776601683795;
BA_ "initialValue" SG_ 510 sig_50_1 1.0;
BA_ "sendPeriod" BO_ 948 1000;
BA_ "crcStartValue" BO_ 948 230;
BA_ "initialValue" SG_ 948 sig_28_30 6215.599250168381;
BA_ "initialValue" SG_ 948 sig_15_15 5.926477660168382E-6;
BA_ "initialValue" SG_ 948 sig_16_1 1.0;
BA_ "initialValue" SG_ 948 sig_27_4 -162.2776601683795;
BA_ "initialValue" SG_ 948 sig_63_2 3.0;
BA_ "sendPeriod" BO_ 105 5;
BA_ "crcStartValue" BO_ 105 79;
BA_ "initialValue" SG_ 105 sig_6_7 102.0;
BA_ "initialValue" SG_ 105 sig_19_16 24729.0;
BA_ "initialValue" SG_ 105 sig_23_4 1.0837722339831621;
BA_ "initialValue" SG_ 105 sig_35_4 -1.1622776601683785E-4;
BA_ "initialValue" SG_ 105 sig_45_6 -6.622776601683777E-5;
BA_ "frameSendMode" BO_ 1756 2;
BA_ "sendPeriod" BO_ 1756 1000;
BA_ "eventMinDistance" BO_ 1756 1000;
BA_ "crcStartValue" BO_ 1756 73;
BA_ "initialValue" SG_ 1756 sig_47_23 0.3140053000000002;
BA_ "initialValue" SG_ 1756 sig_22_12 0.0070972776601683826;
BA_ "initialValue" SG_ 1756 sig_14_6 -40.0;
BA_ "initialValue" SG_ 1756 sig_34_6 4662.27766016838;
BA_ "initialValue" SG_ 1756 sig_56_1 1.0;
BA_ "sendPeriod" BO_ 853 100;
BA_ "crcStartValue" BO_ 853 60;
BA_ "initialValue" SG_ 853 sig_36_3 3.0;
BA_ "initialValue" SG_ 853 sig_20_9 435.0;
BA_ "initialValue" SG_ 853 sig_12_7 42.0;
BA_ "initialValue" SG_ 853 sig_19_1 1.0;
BA_ "initialValue" SG_ 853 sig_34_2 -2.0;
BA_ "initialValue" SG_ 853 sig_43_9 71.0;
BA_ "initialValue" SG_ 853 sig_39_3 6.0;
BA_ "initialValue" SG_ 853 sig_42_1 1.0;
BA_ "initialValue" SG_ 853 sig_54_3 4.0;
BA_ "sendPeriod" BO_ 988 10000;
BA_ "crcStartValue" BO_ 988 27;
BA_ "initialValue" SG_ 988 sig_8_20 -347162.0;
BA_ "initialValue" SG_ 988 sig_7_7 -0.004800000000000002;
BA_ "initialValue" SG_ 988 sig_32_8 1.2762277660168382;
BA_ "frameSendMode" BO_ 200 2;
BA_ "sendPeriod" BO_ 200 10000;
BA_ "eventMinDistance" BO_ 200 1000;
BA_ "crcStartValue" BO_ 200 137;
BA_ "initialValue" SG_ 200 sig_17_17 38000.0;
BA_ "initialValue" SG_ 200 sig_8_8 1.7962277660168386E-4;
BA_ "initialValue" SG_ 200 sig_21_2 2.0;
BA_ "initialValue" SG_ 200 sig_23_2 -2.0;
BA_ "initialValue" SG_ 200 sig_40_9 480.0;
BA_ "initialValue" SG_ 200 sig_47_7 -18.0;
BA_ "sendPeriod" BO_ 2 10000;
BA_ "crcStartValue" BO_ 2 205;
BA_ "initialValue" SG_ 2 sig_1_12 2469.0;
BA_ "initialValue" SG_ 2 sig_0_1 1.0;
BA_ "initialValue" SG_ 2 sig_15_2 -1.0;
BA_ "initialValue" SG_ 2 sig_24_16 50562.0;
BA_ "sendPeriod" BO_ 1660 20;
BA_ "crcStartValue" BO_ 1660 92;
BA_ "initialValue" SG_ 1660 sig_3_18 117880.0;
BA_ "initialValue" SG_ 1660 sig_2_3 2.0;
BA_ "initialValue" SG_ 1660 sig_21_3 4.0;
BA_ "initialValue" SG_ 1660 sig_36_14 1781.0;
BA_ "initialValue" SG_ 1660 sig_35_4 -1.8377223398316238E-6;
BA_ "initialValue" SG_ 1660 sig_55_6 0.020000000000000004;
BA_ "crcStartValue" BO_ 1875 200;
BA_ "initialValue" SG_ 1875 sig_7_16 16857.0;
BA_ "initialValue" SG_ 1875 sig_30_17 -0.02075700000000001;
BA_ "initialValue" SG_ 1875 sig_29_6 21.0;
BA_ "frameSendMode" BO_ 1444 2;
BA_ "sendPeriod" BO_ 1444 500;
BA_ "eventMinDistance" BO_ 1444 500;
BA_ "crcStartValue" BO_ 1444 134;
BA_ "initialValue" SG_ 1444 sig_4_8 0.14377223398316213;
BA_ "initialValue" SG_ 1444 sig_7_2 3.0;
BA_ "initialValue" SG_ 1444 sig_5_1 1.0;
BA_ "initialValue" SG_ 1444 sig_12_5 12000.0;
BA_ "initialValue" SG_ 1444 sig_57_2 3.0;
BA_ "initialValue" SG_ 1444 sig_37_12 -1242.0;
BA_ "initialValue" SG_ 1444 sig_31_10 842.2277660168379;
BA_ "initialValue" SG_ 1444 sig_40_12 -4.3527766016837784E-4;
BA_ "initialValue" SG_ 1444 sig_41_1 1.0;
BA_ "initialValue" SG_ 1444 sig_60_3 2.0;
